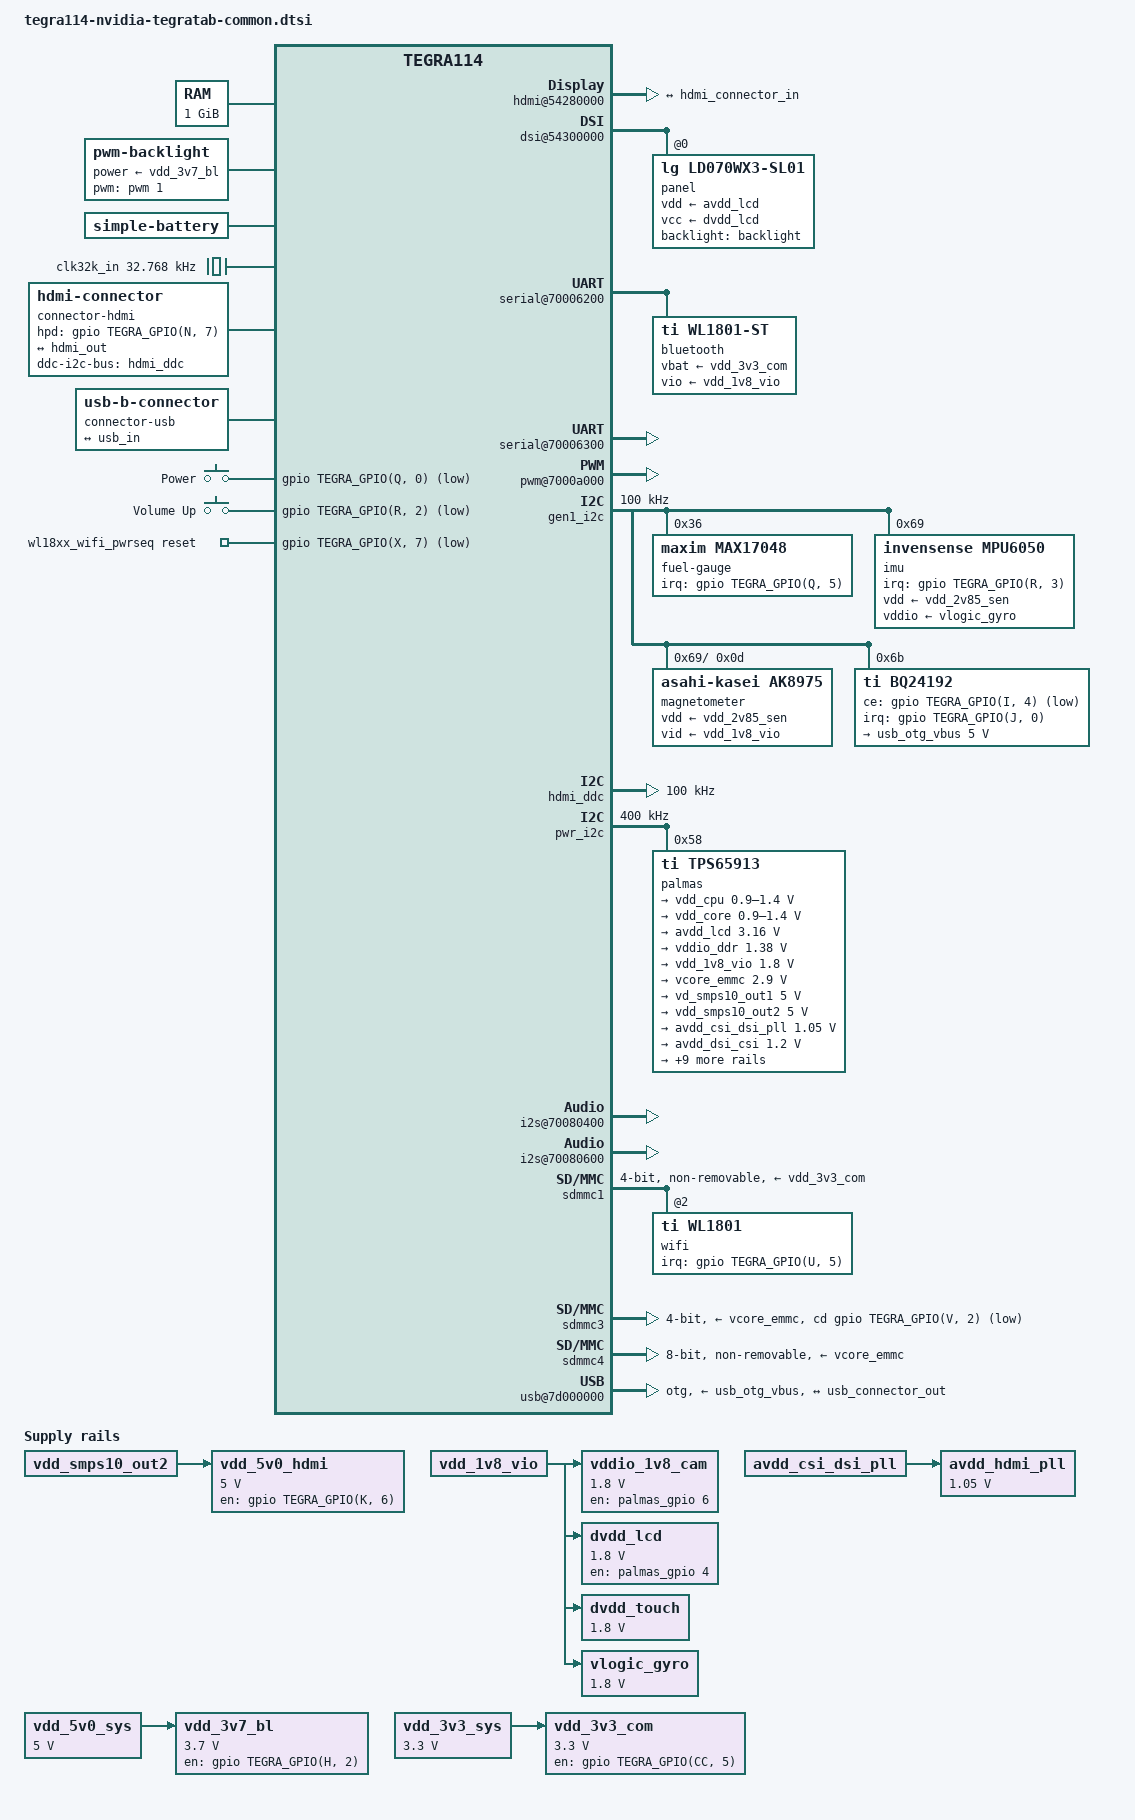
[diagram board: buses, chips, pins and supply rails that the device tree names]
// SPDX-License-Identifier: GPL-2.0

#include <dt-bindings/input/gpio-keys.h>
#include <dt-bindings/input/input.h>
#include <dt-bindings/thermal/thermal.h>

#include "tegra114.dtsi"

/ {
	compatible = "nvidia,tn7", "nvidia,tegra114";
	chassis-type = "tablet";

	aliases {
		mmc0 = &sdmmc4; /* eMMC */
		mmc1 = &sdmmc3; /* uSD slot */
		mmc2 = &sdmmc1; /* WiFi */

		rtc0 = &palmas;
		rtc1 = "/rtc@7000e000";

		serial0 = &uartd; /* Console */
		serial1 = &uartc; /* Bluetooth */
	};

	chosen {
		stdout-path = "serial0:115200n8";
	};

	firmware {
		trusted-foundations {
			compatible = "tlm,trusted-foundations";
			tlm,version-major = <2>;
			tlm,version-minor = <8>;
		};
	};

	memory@80000000 {
		reg = <0x80000000 0x40000000>;
	};

	reserved-memory {
		#address-cells = <1>;
		#size-cells = <1>;
		ranges;

		linux,cma@80000000 {
			compatible = "shared-dma-pool";
			alloc-ranges = <0x80000000 0x30000000>;
			size = <0x10000000>;		/* 256MiB */
			linux,cma-default;
			reusable;
		};

		bootloader-firmware@b7e00000 {
			reg = <0xb7e00000 0x8000000>;   /* 128MB */
			no-map;
		};

		trustzone@bfe00000 {
			reg = <0xbfe00000 0x200000>;	/* 2MB */
			no-map;
		};
	};

	host1x@50000000 {
		hdmi@54280000 {
			status = "okay";

			hdmi-supply = <&vdd_5v0_hdmi>;
			pll-supply = <&avdd_hdmi_pll>;
			vdd-supply = <&avdd_hdmi>;

			port@0 {
				hdmi_out: endpoint {
					remote-endpoint = <&hdmi_connector_in>;
				};
			};
		};

		dsi@54300000 {
			status = "okay";

			avdd-dsi-csi-supply = <&avdd_dsi_csi>;

			panel@0 {
				compatible = "lg,ld070wx3-sl01";
				reg = <0>;

				vdd-supply = <&avdd_lcd>;
				vcc-supply = <&dvdd_lcd>;

				backlight = <&backlight>;
			};
		};
	};

	clock@60006000 {
		emc-timings-1 {
			nvidia,ram-code = <1>;

			timing-12750000 {
				clock-frequency = <12750000>;
				nvidia,parent-clock-frequency = <408000000>;
				clocks = <&tegra_car TEGRA114_CLK_PLL_P>;
				clock-names = "emc-parent";
			};

			timing-20400000 {
				clock-frequency = <20400000>;
				nvidia,parent-clock-frequency = <408000000>;
				clocks = <&tegra_car TEGRA114_CLK_PLL_P>;
				clock-names = "emc-parent";
			};

			timing-40800000 {
				clock-frequency = <40800000>;
				nvidia,parent-clock-frequency = <408000000>;
				clocks = <&tegra_car TEGRA114_CLK_PLL_P>;
				clock-names = "emc-parent";
			};

			timing-68000000 {
				clock-frequency = <68000000>;
				nvidia,parent-clock-frequency = <408000000>;
				clocks = <&tegra_car TEGRA114_CLK_PLL_P>;
				clock-names = "emc-parent";
			};

			timing-102000000 {
				clock-frequency = <102000000>;
				nvidia,parent-clock-frequency = <408000000>;
				clocks = <&tegra_car TEGRA114_CLK_PLL_P>;
				clock-names = "emc-parent";
			};

			timing-204000000 {
				clock-frequency = <204000000>;
				nvidia,parent-clock-frequency = <408000000>;
				clocks = <&tegra_car TEGRA114_CLK_PLL_P>;
				clock-names = "emc-parent";
			};

			timing-312000000 {
				clock-frequency = <312000000>;
				nvidia,parent-clock-frequency = <624000000>;
				clocks = <&tegra_car TEGRA114_CLK_PLL_C>;
				clock-names = "emc-parent";
			};

			timing-408000000 {
				clock-frequency = <408000000>;
				nvidia,parent-clock-frequency = <408000000>;
				clocks = <&tegra_car TEGRA114_CLK_PLL_P>;
				clock-names = "emc-parent";
			};

			timing-624000000 {
				clock-frequency = <624000000>;
				nvidia,parent-clock-frequency = <624000000>;
				clocks = <&tegra_car TEGRA114_CLK_PLL_C>;
				clock-names = "emc-parent";
			};

			timing-792000000 {
				clock-frequency = <792000000>;
				nvidia,parent-clock-frequency = <792000000>;
				clocks = <&tegra_car TEGRA114_CLK_PLL_M>;
				clock-names = "emc-parent";
			};
		};
	};

//	gpio@6000d000 {
//		otg-iusb-hog {
//			gpio-hog;
//			gpios = <TEGRA_GPIO(I, 4) GPIO_ACTIVE_HIGH>;
//			output-high;
//		};
//		rt5639-codec-hog {
//			gpio-hog;
//			gpios = <TEGRA_GPIO(P, 3) GPIO_ACTIVE_HIGH>,
//				<TEGRA_GPIO(P, 1) GPIO_ACTIVE_HIGH>,
//				<TEGRA_GPIO(V, 0) GPIO_ACTIVE_HIGH>;
//			output-high;
//		};
//	};

	vde@6001a000 {
		assigned-clocks = <&tegra_car TEGRA114_CLK_VDE>;
		assigned-clock-parents = <&tegra_car TEGRA114_CLK_PLL_P>;
		assigned-clock-rates = <408000000>;
	};

	pinmux@70000868 {
		pinctrl-names = "default";
		pinctrl-0 = <&state_default>;

		state_default: pinmux {
			/* ULPI pinmux */
			ulpi-data0 {
				nvidia,pins = "ulpi_data0_po1",
					      "ulpi_data1_po2",
					      "ulpi_data2_po3",
					      "ulpi_data5_po6",
					      "ulpi_data6_po7",
					      "ulpi_data7_po0";
				nvidia,function = "ulpi";
				nvidia,pull = <TEGRA_PIN_PULL_NONE>;
				nvidia,tristate = <TEGRA_PIN_DISABLE>;
				nvidia,enable-input = <TEGRA_PIN_ENABLE>;
			};
			ulpi-data3 {
				nvidia,pins = "ulpi_data3_po4",
					      "ulpi_data4_po5";
				nvidia,function = "ulpi";
				nvidia,pull = <TEGRA_PIN_PULL_UP>;
				nvidia,tristate = <TEGRA_PIN_DISABLE>;
				nvidia,enable-input = <TEGRA_PIN_ENABLE>;
			};

			/* SPI1 pinmux */
			ulpi-clk {
				nvidia,pins = "ulpi_clk_py0",
					      "ulpi_nxt_py2",
					      "ulpi_stp_py3";
				nvidia,function = "spi1";
				nvidia,pull = <TEGRA_PIN_PULL_NONE>;
				nvidia,tristate = <TEGRA_PIN_DISABLE>;
				nvidia,enable-input = <TEGRA_PIN_DISABLE>;
			};
			ulpi-dir {
				nvidia,pins = "ulpi_dir_py1";
				nvidia,function = "spi1";
				nvidia,pull = <TEGRA_PIN_PULL_NONE>;
				nvidia,tristate = <TEGRA_PIN_DISABLE>;
				nvidia,enable-input = <TEGRA_PIN_ENABLE>;
			};

			/* I2S pinmux */
			dap1-pins {
				nvidia,pins = "dap1_fs_pn0",
					      "dap1_din_pn1",
					      "dap1_dout_pn2",
					      "dap1_sclk_pn3";
				nvidia,function = "rsvd4";
				nvidia,pull = <TEGRA_PIN_PULL_DOWN>;
				nvidia,tristate = <TEGRA_PIN_ENABLE>;
				nvidia,enable-input = <TEGRA_PIN_DISABLE>;
			};
			dap2-dout {
				nvidia,pins = "dap2_fs_pa2",
					      "dap2_sclk_pa3",
					      "dap2_dout_pa5";
				nvidia,function = "i2s1";
				nvidia,pull = <TEGRA_PIN_PULL_NONE>;
				nvidia,tristate = <TEGRA_PIN_DISABLE>;
				nvidia,enable-input = <TEGRA_PIN_DISABLE>;
			};
			dap2-din {
				nvidia,pins = "dap2_din_pa4";
				nvidia,function = "i2s1";
				nvidia,pull = <TEGRA_PIN_PULL_NONE>;
				nvidia,tristate = <TEGRA_PIN_DISABLE>;
				nvidia,enable-input = <TEGRA_PIN_ENABLE>;
			};
			dap3-fs-pp0 {
				nvidia,pins = "dap3_fs_pp0",
					      "dap3_din_pp1",
					      "dap3_dout_pp2",
					      "dap3_sclk_pp3";
				nvidia,function = "i2s2";
				nvidia,pull = <TEGRA_PIN_PULL_DOWN>;
				nvidia,tristate = <TEGRA_PIN_ENABLE>;
				nvidia,enable-input = <TEGRA_PIN_DISABLE>;
			};
			pv0 {
				nvidia,pins = "pv0";
				nvidia,function = "rsvd2";
				nvidia,pull = <TEGRA_PIN_PULL_DOWN>;
				nvidia,tristate = <TEGRA_PIN_ENABLE>;
				nvidia,enable-input = <TEGRA_PIN_DISABLE>;
			};
			pv1 {
				nvidia,pins = "pv1";
				nvidia,function = "rsvd1";
				nvidia,pull = <TEGRA_PIN_PULL_DOWN>;
				nvidia,tristate = <TEGRA_PIN_ENABLE>;
				nvidia,enable-input = <TEGRA_PIN_DISABLE>;
			};
			dap4-din {
				nvidia,pins = "dap4_din_pp5";
				nvidia,function = "i2s3";
				nvidia,pull = <TEGRA_PIN_PULL_NONE>;
				nvidia,tristate = <TEGRA_PIN_DISABLE>;
				nvidia,enable-input = <TEGRA_PIN_ENABLE>;
			};
			dap4-dout {
				nvidia,pins = "dap4_fs_pp4",
					      "dap4_dout_pp6",
					      "dap4_sclk_pp7";
				nvidia,function = "i2s3";
				nvidia,pull = <TEGRA_PIN_PULL_NONE>;
				nvidia,tristate = <TEGRA_PIN_DISABLE>;
				nvidia,enable-input = <TEGRA_PIN_DISABLE>;
			};

			/* SDMMC1 pinmux */
			sdmmc1-clk {
				nvidia,pins = "sdmmc1_clk_pz0";
				nvidia,function = "sdmmc1";
				nvidia,pull = <TEGRA_PIN_PULL_NONE>;
				nvidia,tristate = <TEGRA_PIN_DISABLE>;
				nvidia,enable-input = <TEGRA_PIN_ENABLE>;
			};
			sdmmc1-cmd {
				nvidia,pins = "sdmmc1_cmd_pz1",
					      "sdmmc1_dat0_py7",
					      "sdmmc1_dat1_py6",
					      "sdmmc1_dat2_py5",
					      "sdmmc1_dat3_py4";
				nvidia,function = "sdmmc1";
				nvidia,pull = <TEGRA_PIN_PULL_UP>;
				nvidia,tristate = <TEGRA_PIN_DISABLE>;
				nvidia,enable-input = <TEGRA_PIN_ENABLE>;
			};
			sdmmc1-wp-n {
				nvidia,pins = "sdmmc1_wp_n_pv3";
				nvidia,function = "sdmmc1";
				nvidia,pull = <TEGRA_PIN_PULL_NONE>;
				nvidia,tristate = <TEGRA_PIN_DISABLE>;
				nvidia,enable-input = <TEGRA_PIN_DISABLE>;
			};

			/* SDMMC3 pinmux */
			sdmmc3-clk {
				nvidia,pins = "sdmmc3_clk_pa6";
				nvidia,function = "sdmmc3";
				nvidia,pull = <TEGRA_PIN_PULL_NONE>;
				nvidia,tristate = <TEGRA_PIN_DISABLE>;
				nvidia,enable-input = <TEGRA_PIN_DISABLE>;
			};
			sdmmc3-cmd {
				nvidia,pins = "sdmmc3_cmd_pa7",
					      "sdmmc3_dat0_pb7",
					      "sdmmc3_dat1_pb6",
					      "sdmmc3_dat2_pb5",
					      "sdmmc3_dat3_pb4",
					      "sdmmc3_cd_n_pv2";
				nvidia,function = "sdmmc3";
				nvidia,pull = <TEGRA_PIN_PULL_UP>;
				nvidia,tristate = <TEGRA_PIN_DISABLE>;
				nvidia,enable-input = <TEGRA_PIN_ENABLE>;
			};
			sdmmc3-clk-lb {
				nvidia,pins = "sdmmc3_clk_lb_out_pee4",
					      "sdmmc3_clk_lb_in_pee5";
				nvidia,function = "sdmmc3";
				nvidia,pull = <TEGRA_PIN_PULL_UP>;
				nvidia,tristate = <TEGRA_PIN_DISABLE>;
				nvidia,enable-input = <TEGRA_PIN_ENABLE>;
			};

			/* SDMMC4 pinmux */
			sdmmc4-clk {
				nvidia,pins = "sdmmc4_clk_pcc4";
				nvidia,function = "sdmmc4";
				nvidia,pull = <TEGRA_PIN_PULL_NONE>;
				nvidia,tristate = <TEGRA_PIN_DISABLE>;
				nvidia,enable-input = <TEGRA_PIN_ENABLE>;
			};
			sdmmc4-cmd {
				nvidia,pins = "sdmmc4_cmd_pt7",
					      "sdmmc4_dat0_paa0",
					      "sdmmc4_dat1_paa1",
					      "sdmmc4_dat2_paa2",
					      "sdmmc4_dat3_paa3",
					      "sdmmc4_dat4_paa4",
					      "sdmmc4_dat5_paa5",
					      "sdmmc4_dat6_paa6",
					      "sdmmc4_dat7_paa7";
				nvidia,function = "sdmmc4";
				nvidia,pull = <TEGRA_PIN_PULL_UP>;
				nvidia,tristate = <TEGRA_PIN_DISABLE>;
				nvidia,enable-input = <TEGRA_PIN_ENABLE>;
			};

			/* EXTPERIPH pinmux */
			clk1-req {
				nvidia,pins = "clk1_req_pee2";
				nvidia,function = "rsvd3";
				nvidia,pull = <TEGRA_PIN_PULL_DOWN>;
				nvidia,tristate = <TEGRA_PIN_ENABLE>;
				nvidia,enable-input = <TEGRA_PIN_DISABLE>;
			};
			clk1-out {
				nvidia,pins = "clk1_out_pw4";
				nvidia,function = "extperiph1";
				nvidia,pull = <TEGRA_PIN_PULL_NONE>;
				nvidia,tristate = <TEGRA_PIN_DISABLE>;
				nvidia,enable-input = <TEGRA_PIN_DISABLE>;
			};
			clk2-req {
				nvidia,pins = "clk2_req_pcc5";
				nvidia,function = "rsvd2";
				nvidia,pull = <TEGRA_PIN_PULL_NONE>;
				nvidia,tristate = <TEGRA_PIN_DISABLE>;
				nvidia,enable-input = <TEGRA_PIN_DISABLE>;
			};
			clk2-out {
				nvidia,pins = "clk2_out_pw5";
				nvidia,function = "extperiph2";
				nvidia,pull = <TEGRA_PIN_PULL_NONE>;
				nvidia,tristate = <TEGRA_PIN_DISABLE>;
				nvidia,enable-input = <TEGRA_PIN_DISABLE>;
			};
			clk3-req-pee1 {
				nvidia,pins = "clk3_req_pee1";
				nvidia,function = "rsvd2";
				nvidia,pull = <TEGRA_PIN_PULL_NONE>;
				nvidia,tristate = <TEGRA_PIN_DISABLE>;
				nvidia,enable-input = <TEGRA_PIN_DISABLE>;
			};
			clk3-out {
				nvidia,pins = "clk3_out_pee0";
				nvidia,function = "extperiph3";
				nvidia,pull = <TEGRA_PIN_PULL_NONE>;
				nvidia,tristate = <TEGRA_PIN_DISABLE>;
				nvidia,enable-input = <TEGRA_PIN_DISABLE>;
			};

			dvfs-pinmux {
				nvidia,pins = "dvfs_pwm_px0",
					      "dvfs_clk_px2";
				nvidia,function = "cldvfs";
				nvidia,pull = <TEGRA_PIN_PULL_NONE>;
				nvidia,tristate = <TEGRA_PIN_DISABLE>;
				nvidia,enable-input = <TEGRA_PIN_DISABLE>;
			};

			/* HDMI pinmux */
			hdmi-irq {
				nvidia,pins = "hdmi_int_pn7";
				nvidia,function = "rsvd1";
				nvidia,pull = <TEGRA_PIN_PULL_DOWN>;
				nvidia,tristate = <TEGRA_PIN_DISABLE>;
				nvidia,enable-input = <TEGRA_PIN_ENABLE>;
				nvidia,rcv-sel = <TEGRA_PIN_DISABLE>;
			};
			hdmi-cec {
				nvidia,pins = "hdmi_cec_pee3";
				nvidia,function = "cec";
				nvidia,pull = <TEGRA_PIN_PULL_NONE>;
				nvidia,tristate = <TEGRA_PIN_DISABLE>;
				nvidia,enable-input = <TEGRA_PIN_ENABLE>;
				nvidia,open-drain = <TEGRA_PIN_DISABLE>;
			};

			/* I2C pinmux */
			gen1-i2c {
				nvidia,pins = "gen1_i2c_scl_pc4",
					      "gen1_i2c_sda_pc5";
				nvidia,function = "i2c1";
				nvidia,pull = <TEGRA_PIN_PULL_NONE>;
				nvidia,tristate = <TEGRA_PIN_DISABLE>;
				nvidia,enable-input = <TEGRA_PIN_ENABLE>;
				nvidia,open-drain = <TEGRA_PIN_ENABLE>;
			};
			gen2-i2c {
				nvidia,pins = "gen2_i2c_scl_pt5",
					      "gen2_i2c_sda_pt6";
				nvidia,function = "i2c2";
				nvidia,pull = <TEGRA_PIN_PULL_NONE>;
				nvidia,tristate = <TEGRA_PIN_DISABLE>;
				nvidia,enable-input = <TEGRA_PIN_ENABLE>;
				nvidia,open-drain = <TEGRA_PIN_ENABLE>;
			};
			cam-i2c {
				nvidia,pins = "cam_i2c_scl_pbb1",
					      "cam_i2c_sda_pbb2";
				nvidia,function = "i2c3";
				nvidia,pull = <TEGRA_PIN_PULL_NONE>;
				nvidia,tristate = <TEGRA_PIN_DISABLE>;
				nvidia,enable-input = <TEGRA_PIN_ENABLE>;
				nvidia,open-drain = <TEGRA_PIN_ENABLE>;
			};
			ddc-scl-pv4 {
				nvidia,pins = "ddc_scl_pv4",
					      "ddc_sda_pv5";
				nvidia,function = "i2c4";
				nvidia,pull = <TEGRA_PIN_PULL_NONE>;
				nvidia,tristate = <TEGRA_PIN_DISABLE>;
				nvidia,enable-input = <TEGRA_PIN_ENABLE>;
				nvidia,rcv-sel = <TEGRA_PIN_DISABLE>;
			};
			pwr-i2c {
				nvidia,pins = "pwr_i2c_scl_pz6",
					      "pwr_i2c_sda_pz7";
				nvidia,function = "i2cpwr";
				nvidia,pull = <TEGRA_PIN_PULL_NONE>;
				nvidia,tristate = <TEGRA_PIN_DISABLE>;
				nvidia,enable-input = <TEGRA_PIN_ENABLE>;
				nvidia,open-drain = <TEGRA_PIN_ENABLE>;
			};

			/* UARTA pinmux */
			uarta-out {
				nvidia,pins = "kb_row9_ps1";
				nvidia,function = "uarta";
				nvidia,pull = <TEGRA_PIN_PULL_NONE>;
				nvidia,tristate = <TEGRA_PIN_DISABLE>;
				nvidia,enable-input = <TEGRA_PIN_DISABLE>;
			};
			uarta-in {
				nvidia,pins = "kb_row10_ps2";
				nvidia,function = "uarta";
				nvidia,pull = <TEGRA_PIN_PULL_NONE>;
				nvidia,tristate = <TEGRA_PIN_DISABLE>;
				nvidia,enable-input = <TEGRA_PIN_ENABLE>;
			};

			/* UARTB pinmux */
			uart2-cts-rts {
				nvidia,pins = "uart2_cts_n_pj5",
					      "uart2_rts_n_pj6";
				nvidia,function = "rsvd3";
				nvidia,pull = <TEGRA_PIN_PULL_DOWN>;
				nvidia,tristate = <TEGRA_PIN_ENABLE>;
				nvidia,enable-input = <TEGRA_PIN_DISABLE>;
			};

			/* UARTC pinmux */
			uart3-cts-rxd {
				nvidia,pins = "uart3_cts_n_pa1",
					      "uart3_rxd_pw7";
				nvidia,function = "uartc";
				nvidia,pull = <TEGRA_PIN_PULL_UP>;
				nvidia,tristate = <TEGRA_PIN_DISABLE>;
				nvidia,enable-input = <TEGRA_PIN_ENABLE>;
			};
			uart3-rts-txd {
				nvidia,pins = "uart3_rts_n_pc0",
					      "uart3_txd_pw6";
				nvidia,function = "uartc";
				nvidia,pull = <TEGRA_PIN_PULL_NONE>;
				nvidia,tristate = <TEGRA_PIN_DISABLE>;
				nvidia,enable-input = <TEGRA_PIN_DISABLE>;
			};

			/* UARTD pinmux */
			gmi-a17 {
				nvidia,pins = "gmi_a17_pb0";
				nvidia,function = "uartd";
				nvidia,pull = <TEGRA_PIN_PULL_UP>;
				nvidia,tristate = <TEGRA_PIN_DISABLE>;
				nvidia,enable-input = <TEGRA_PIN_ENABLE>;
			};
			gmi-a18 {
				nvidia,pins = "gmi_a18_pb1";
				nvidia,function = "uartd";
				nvidia,pull = <TEGRA_PIN_PULL_NONE>;
				nvidia,tristate = <TEGRA_PIN_DISABLE>;
				nvidia,enable-input = <TEGRA_PIN_ENABLE>;
			};
			uartd-out {
				nvidia,pins = "gmi_a16_pj7",
					      "gmi_a19_pk7";
				nvidia,function = "uartd";
				nvidia,pull = <TEGRA_PIN_PULL_NONE>;
				nvidia,tristate = <TEGRA_PIN_DISABLE>;
				nvidia,enable-input = <TEGRA_PIN_DISABLE>;
			};

			/* PORT U */
			pu0 {
				nvidia,pins = "pu0";
				nvidia,function = "rsvd3";
				nvidia,pull = <TEGRA_PIN_PULL_DOWN>;
				nvidia,tristate = <TEGRA_PIN_ENABLE>;
				nvidia,enable-input = <TEGRA_PIN_DISABLE>;
			};
			pu1-2 {
				nvidia,pins = "pu1", "pu2";
				nvidia,function = "rsvd1";
				nvidia,pull = <TEGRA_PIN_PULL_DOWN>;
				nvidia,tristate = <TEGRA_PIN_ENABLE>;
				nvidia,enable-input = <TEGRA_PIN_DISABLE>;
			};
			pu3 {
				nvidia,pins = "pu3";
				nvidia,function = "pwm0";
				nvidia,pull = <TEGRA_PIN_PULL_DOWN>;
				nvidia,tristate = <TEGRA_PIN_ENABLE>;
				nvidia,enable-input = <TEGRA_PIN_DISABLE>;
			};
			pu4 {
				nvidia,pins = "pu4";
				nvidia,function = "pwm1";
				nvidia,pull = <TEGRA_PIN_PULL_DOWN>;
				nvidia,tristate = <TEGRA_PIN_ENABLE>;
				nvidia,enable-input = <TEGRA_PIN_DISABLE>;
			};
			pu5 {
				nvidia,pins = "pu5";
				nvidia,function = "pwm2";
				nvidia,pull = <TEGRA_PIN_PULL_UP>;
				nvidia,tristate = <TEGRA_PIN_DISABLE>;
				nvidia,enable-input = <TEGRA_PIN_ENABLE>;
			};
			pu6 {
				nvidia,pins = "pu6";
				nvidia,function = "pwm3";
				nvidia,pull = <TEGRA_PIN_PULL_NONE>;
				nvidia,tristate = <TEGRA_PIN_DISABLE>;
				nvidia,enable-input = <TEGRA_PIN_ENABLE>;
			};

			/* GMI section */
			gmi-wp-n-pc7 {
				nvidia,pins = "gmi_wp_n_pc7",
					      "gmi_adv_n_pk0",
					      "gmi_cs0_n_pj0",
					      "gmi_wr_n_pi0";
				nvidia,function = "rsvd1";
				nvidia,pull = <TEGRA_PIN_PULL_UP>;
				nvidia,tristate = <TEGRA_PIN_DISABLE>;
				nvidia,enable-input = <TEGRA_PIN_ENABLE>;
			};
			gmi-iordy-pi5 {
				nvidia,pins = "gmi_iordy_pi5";
				nvidia,function = "rsvd2";
				nvidia,pull = <TEGRA_PIN_PULL_DOWN>;
				nvidia,tristate = <TEGRA_PIN_ENABLE>;
				nvidia,enable-input = <TEGRA_PIN_DISABLE>;
			};
			gmi-wait-pi7 {
				nvidia,pins = "gmi_wait_pi7";
				nvidia,function = "nand";
				nvidia,pull = <TEGRA_PIN_PULL_NONE>;
				nvidia,tristate = <TEGRA_PIN_DISABLE>;
				nvidia,enable-input = <TEGRA_PIN_DISABLE>;
			};
			gmi-clk-pk1 {
				nvidia,pins = "gmi_clk_pk1",
					      "gmi_ad10_ph2",
					      "gmi_ad11_ph3",
					      "gmi_ad14_ph6",
					      "gmi_cs3_n_pk4";
				nvidia,function = "gmi";
				nvidia,pull = <TEGRA_PIN_PULL_NONE>;
				nvidia,tristate = <TEGRA_PIN_DISABLE>;
				nvidia,enable-input = <TEGRA_PIN_DISABLE>;
			};
			gmi-cs2-n-pk3 {
				nvidia,pins = "gmi_cs2_n_pk3";
				nvidia,function = "gmi";
				nvidia,pull = <TEGRA_PIN_PULL_UP>;
				nvidia,tristate = <TEGRA_PIN_DISABLE>;
				nvidia,enable-input = <TEGRA_PIN_ENABLE>;
			};
			gmi-cs4-n-pk2 {
				nvidia,pins = "gmi_cs4_n_pk2";
				nvidia,function = "gmi";
				nvidia,pull = <TEGRA_PIN_PULL_NONE>;
				nvidia,tristate = <TEGRA_PIN_ENABLE>;
				nvidia,enable-input = <TEGRA_PIN_ENABLE>;
			};
			gmi-cs6-n-pi3 {
				nvidia,pins = "gmi_cs6_n_pi3";
				nvidia,function = "nand";
				nvidia,pull = <TEGRA_PIN_PULL_DOWN>;
				nvidia,tristate = <TEGRA_PIN_ENABLE>;
				nvidia,enable-input = <TEGRA_PIN_DISABLE>;
			};
			gmi-cs7-n-pi6 {
				nvidia,pins = "gmi_cs7_n_pi6";
				nvidia,function = "nand";
				nvidia,pull = <TEGRA_PIN_PULL_NONE>;
				nvidia,tristate = <TEGRA_PIN_DISABLE>;
				nvidia,enable-input = <TEGRA_PIN_ENABLE>;
			};
			gmi-ad0-pg0 {
				nvidia,pins = "gmi_ad0_pg0";
				nvidia,function = "rsvd1";
				nvidia,pull = <TEGRA_PIN_PULL_NONE>;
				nvidia,tristate = <TEGRA_PIN_DISABLE>;
				nvidia,enable-input = <TEGRA_PIN_DISABLE>;
			};
			gmi-ad1-pg1 {
				nvidia,pins = "gmi_ad1_pg1",
					      "gmi_ad4_pg4",
					      "gmi_ad5_pg5",
					      "gmi_ad6_pg6",
					      "gmi_ad7_pg7";
				nvidia,function = "rsvd1";
				nvidia,pull = <TEGRA_PIN_PULL_DOWN>;
				nvidia,tristate = <TEGRA_PIN_ENABLE>;
				nvidia,enable-input = <TEGRA_PIN_DISABLE>;
			};
			gmi-ad2-pg2 {
				nvidia,pins = "gmi_ad2_pg2",
					      "gmi_ad3_pg3",
					      "gmi_oe_n_pi1";
				nvidia,function = "rsvd1";
				nvidia,pull = <TEGRA_PIN_PULL_NONE>;
				nvidia,tristate = <TEGRA_PIN_DISABLE>;
				nvidia,enable-input = <TEGRA_PIN_ENABLE>;
			};
			gmi-ad8-ph0 {
				nvidia,pins = "gmi_ad8_ph0";
				nvidia,function = "gmi";
				nvidia,pull = <TEGRA_PIN_PULL_DOWN>;
				nvidia,tristate = <TEGRA_PIN_ENABLE>;
				nvidia,enable-input = <TEGRA_PIN_DISABLE>;
			};
			gmi-ad9 {
				nvidia,pins = "gmi_ad9_ph1";
				nvidia,function = "pwm1";
				nvidia,pull = <TEGRA_PIN_PULL_NONE>;
				nvidia,tristate = <TEGRA_PIN_DISABLE>;
				nvidia,enable-input = <TEGRA_PIN_DISABLE>;
			};
			gmi-ad12-ph4 {
				nvidia,pins = "gmi_ad12_ph4";
				nvidia,function = "rsvd4";
				nvidia,pull = <TEGRA_PIN_PULL_UP>;
				nvidia,tristate = <TEGRA_PIN_DISABLE>;
				nvidia,enable-input = <TEGRA_PIN_ENABLE>;
			};
			gmi-ad13-ph5 {
				nvidia,pins = "gmi_ad13_ph5";
				nvidia,function = "rsvd4";
				nvidia,pull = <TEGRA_PIN_PULL_NONE>;
				nvidia,tristate = <TEGRA_PIN_DISABLE>;
				nvidia,enable-input = <TEGRA_PIN_DISABLE>;
			};
			gmi-ad15-ph7 {
				nvidia,pins = "gmi_ad15_ph7";
				nvidia,function = "gmi";
				nvidia,pull = <TEGRA_PIN_PULL_DOWN>;
				nvidia,tristate = <TEGRA_PIN_ENABLE>;
				nvidia,enable-input = <TEGRA_PIN_DISABLE>;
			};
			gmi-dqs-p-pj3 {
				nvidia,pins = "gmi_dqs_p_pj3";
				nvidia,function = "nand";
				nvidia,pull = <TEGRA_PIN_PULL_UP>;
				nvidia,tristate = <TEGRA_PIN_DISABLE>;
				nvidia,enable-input = <TEGRA_PIN_ENABLE>;
			};
			gmi-rst-n-pi4 {
				nvidia,pins = "gmi_rst_n_pi4";
				nvidia,function = "rsvd4";
				nvidia,pull = <TEGRA_PIN_PULL_NONE>;
				nvidia,tristate = <TEGRA_PIN_DISABLE>;
				nvidia,enable-input = <TEGRA_PIN_DISABLE>;
			};
			gmi-clk-lb {
				nvidia,pins = "gmi_clk_lb";
				nvidia,function = "gmi";
				nvidia,pull = <TEGRA_PIN_PULL_NONE>;
				nvidia,tristate = <TEGRA_PIN_DISABLE>;
				nvidia,enable-input = <TEGRA_PIN_ENABLE>;
			};

			/* VI_ALT3 pinmux */
			cam-mclk {
				nvidia,pins = "pbb0", "cam_mclk_pcc0";
				nvidia,function = "vi_alt3";
				nvidia,pull = <TEGRA_PIN_PULL_NONE>;
				nvidia,tristate = <TEGRA_PIN_DISABLE>;
				nvidia,enable-input = <TEGRA_PIN_DISABLE>;
			};

			port-bb {
				nvidia,pins = "pbb3", "pbb4", "pbb5",
					      "pbb6",	"pbb7";
				nvidia,function = "rsvd4";
				nvidia,pull = <TEGRA_PIN_PULL_NONE>;
				nvidia,tristate = <TEGRA_PIN_DISABLE>;
				nvidia,enable-input = <TEGRA_PIN_DISABLE>;
			};

			port-cc {
				nvidia,pins = "pcc1", "pcc2";
				nvidia,function = "rsvd2";
				nvidia,pull = <TEGRA_PIN_PULL_DOWN>;
				nvidia,tristate = <TEGRA_PIN_DISABLE>;
				nvidia,enable-input = <TEGRA_PIN_ENABLE>;
			};

			jtag-rtck {
				nvidia,pins = "jtag_rtck";
				nvidia,function = "rtck";
				nvidia,pull = <TEGRA_PIN_PULL_NONE>;
				nvidia,tristate = <TEGRA_PIN_DISABLE>;
				nvidia,enable-input = <TEGRA_PIN_ENABLE>;
			};

			/* KBC pinmux */
			kb-row0-pr0 {
				nvidia,pins = "kb_row0_pr0",
					      "kb_row1_pr1";
				nvidia,function = "rsvd2";
				nvidia,pull = <TEGRA_PIN_PULL_NONE>;
				nvidia,tristate = <TEGRA_PIN_DISABLE>;
				nvidia,enable-input = <TEGRA_PIN_DISABLE>;
			};
			kb-row2-pr2 {
				nvidia,pins = "kb_row2_pr2",
					      "kb_col0_pq0";
				nvidia,function = "kbc";
				nvidia,pull = <TEGRA_PIN_PULL_UP>;
				nvidia,tristate = <TEGRA_PIN_DISABLE>;
				nvidia,enable-input = <TEGRA_PIN_ENABLE>;
			};
			kb-row3-pr3 {
				nvidia,pins = "kb_row3_pr3";
				nvidia,function = "rsvd3";
				nvidia,pull = <TEGRA_PIN_PULL_UP>;
				nvidia,tristate = <TEGRA_PIN_DISABLE>;
				nvidia,enable-input = <TEGRA_PIN_ENABLE>;
			};
			kb-row4-pr4 {
				nvidia,pins = "kb_row4_pr4",
					      "kb_row5_pr5",
					      "kb_row6_pr6",
					      "kb_col3_pq3",
					      "kb_col4_pq4";
				nvidia,function = "kbc";
				nvidia,pull = <TEGRA_PIN_PULL_DOWN>;
				nvidia,tristate = <TEGRA_PIN_ENABLE>;
				nvidia,enable-input = <TEGRA_PIN_DISABLE>;
			};
			kb-row7-pr7 {
				nvidia,pins = "kb_row7_pr7",
					      "kb_col2_pq2",
					      "kb_col5_pq5";
				nvidia,function = "rsvd2";
				nvidia,pull = <TEGRA_PIN_PULL_UP>;
				nvidia,tristate = <TEGRA_PIN_DISABLE>;
				nvidia,enable-input = <TEGRA_PIN_ENABLE>;
			};
			kb-row8-ps0 {
				nvidia,pins = "kb_row8_ps0",
					      "kb_col1_pq1",
					      "kb_col6_pq6",
					      "kb_col7_pq7";
				nvidia,function = "rsvd2";
				nvidia,pull = <TEGRA_PIN_PULL_DOWN>;
				nvidia,tristate = <TEGRA_PIN_ENABLE>;
				nvidia,enable-input = <TEGRA_PIN_DISABLE>;
			};

			/* CORE pinmux */
			sys-clk-req {
				nvidia,pins = "sys_clk_req_pz5";
				nvidia,function = "rsvd2";
				nvidia,pull = <TEGRA_PIN_PULL_DOWN>;
				nvidia,tristate = <TEGRA_PIN_ENABLE>;
				nvidia,enable-input = <TEGRA_PIN_DISABLE>;
			};
			clk-32k-out {
				nvidia,pins = "clk_32k_out_pa0",
					      "gmi_cs1_n_pj2";
				nvidia,function = "soc";
				nvidia,pull = <TEGRA_PIN_PULL_UP>;
				nvidia,tristate = <TEGRA_PIN_ENABLE>;
				nvidia,enable-input = <TEGRA_PIN_ENABLE>;
			};
			clk-32k-in {
				nvidia,pins = "clk_32k_in";
				nvidia,function = "clk";
				nvidia,pull = <TEGRA_PIN_PULL_NONE>;
				nvidia,tristate = <TEGRA_PIN_DISABLE>;
				nvidia,enable-input = <TEGRA_PIN_ENABLE>;
			};
			core-pwr-req {
				nvidia,pins = "core_pwr_req";
				nvidia,function = "pwron";
				nvidia,pull = <TEGRA_PIN_PULL_NONE>;
				nvidia,tristate = <TEGRA_PIN_DISABLE>;
				nvidia,enable-input = <TEGRA_PIN_DISABLE>;
			};
			cpu-pwr-req {
				nvidia,pins = "cpu_pwr_req";
				nvidia,function = "cpu";
				nvidia,pull = <TEGRA_PIN_PULL_NONE>;
				nvidia,tristate = <TEGRA_PIN_DISABLE>;
				nvidia,enable-input = <TEGRA_PIN_DISABLE>;
			};
			pwr-int-n {
				nvidia,pins = "pwr_int_n";
				nvidia,function = "pmi";
				nvidia,pull = <TEGRA_PIN_PULL_UP>;
				nvidia,tristate = <TEGRA_PIN_DISABLE>;
				nvidia,enable-input = <TEGRA_PIN_ENABLE>;
			};
			owr {
				nvidia,pins = "owr";
				nvidia,function = "rsvd2";
				nvidia,pull = <TEGRA_PIN_PULL_DOWN>;
				nvidia,tristate = <TEGRA_PIN_ENABLE>;
				nvidia,enable-input = <TEGRA_PIN_DISABLE>;
				nvidia,rcv-sel = <TEGRA_PIN_DISABLE>;
			};
			reset-out-n {
				nvidia,pins = "reset_out_n";
				nvidia,function = "reset_out_n";
				nvidia,pull = <TEGRA_PIN_PULL_NONE>;
				nvidia,tristate = <TEGRA_PIN_DISABLE>;
				nvidia,enable-input = <TEGRA_PIN_DISABLE>;
			};

			/* AUD pinmux */
			gpio-x1-aud-px1 {
				nvidia,pins = "gpio_x1_aud_px1";
				nvidia,function = "rsvd2";
				nvidia,pull = <TEGRA_PIN_PULL_UP>;
				nvidia,tristate = <TEGRA_PIN_DISABLE>;
				nvidia,enable-input = <TEGRA_PIN_ENABLE>;
			};
			gpio-x3-aud-px3 {
				nvidia,pins = "gpio_x3_aud_px3";
				nvidia,function = "rsvd3";
				nvidia,pull = <TEGRA_PIN_PULL_DOWN>;
				nvidia,tristate = <TEGRA_PIN_ENABLE>;
				nvidia,enable-input = <TEGRA_PIN_DISABLE>;
			};
			gpio-x4-aud-px4 {
				nvidia,pins = "gpio_x4_aud_px4",
					      "gpio_x5_aud_px5",
					      "gpio_x7_aud_px7";
				nvidia,function = "rsvd1";
				nvidia,pull = <TEGRA_PIN_PULL_DOWN>;
				nvidia,tristate = <TEGRA_PIN_ENABLE>;
				nvidia,enable-input = <TEGRA_PIN_DISABLE>;
			};
			gpio-x6-aud-px6 {
				nvidia,pins = "gpio_x6_aud_px6";
				nvidia,function = "rsvd4";
				nvidia,pull = <TEGRA_PIN_PULL_DOWN>;
				nvidia,tristate = <TEGRA_PIN_ENABLE>;
				nvidia,enable-input = <TEGRA_PIN_DISABLE>;
			};
			gpio-w2-aud-pw2 {
				nvidia,pins = "gpio_w2_aud_pw2";
				nvidia,function = "rsvd2";
				nvidia,pull = <TEGRA_PIN_PULL_DOWN>;
				nvidia,tristate = <TEGRA_PIN_ENABLE>;
				nvidia,enable-input = <TEGRA_PIN_DISABLE>;
			};
			gpio-w3-aud-pw3 {
				nvidia,pins = "gpio_w3_aud_pw3";
				nvidia,function = "spi6";
				nvidia,pull = <TEGRA_PIN_PULL_UP>;
				nvidia,tristate = <TEGRA_PIN_DISABLE>;
				nvidia,enable-input = <TEGRA_PIN_ENABLE>;
			};

			usb-vbus-en {
				nvidia,pins = "usb_vbus_en0_pn4",
					      "usb_vbus_en1_pn5";
				nvidia,function = "rsvd2";
				nvidia,pull = <TEGRA_PIN_PULL_DOWN>;
				nvidia,tristate = <TEGRA_PIN_ENABLE>;
				nvidia,enable-input = <TEGRA_PIN_DISABLE>;
				nvidia,open-drain = <TEGRA_PIN_DISABLE>;
			};

			/* GPIO power/drive control */
			drive-sdio1 {
				nvidia,pins = "drive_sdio1";
				nvidia,high-speed-mode = <TEGRA_PIN_ENABLE>;
				nvidia,schmitt = <TEGRA_PIN_DISABLE>;
				nvidia,pull-down-strength = <36>;
				nvidia,pull-up-strength = <20>;
				nvidia,slew-rate-rising = <TEGRA_PIN_SLEW_RATE_SLOW>;
				nvidia,slew-rate-falling = <TEGRA_PIN_SLEW_RATE_SLOW>;
			};
			drive-sdio3 {
				nvidia,pins = "drive_sdio3";
				nvidia,high-speed-mode = <TEGRA_PIN_ENABLE>;
				nvidia,schmitt = <TEGRA_PIN_DISABLE>;
				nvidia,pull-down-strength = <22>;
				nvidia,pull-up-strength = <36>;
				nvidia,slew-rate-rising = <TEGRA_PIN_SLEW_RATE_FASTEST>;
				nvidia,slew-rate-falling = <TEGRA_PIN_SLEW_RATE_FASTEST>;
			};
			drive-gma {
				nvidia,pins = "drive_gma";
				nvidia,high-speed-mode = <TEGRA_PIN_ENABLE>;
				nvidia,schmitt = <TEGRA_PIN_DISABLE>;
				nvidia,pull-down-strength = <2>;
				nvidia,pull-up-strength = <2>;
				nvidia,slew-rate-rising = <TEGRA_PIN_SLEW_RATE_FASTEST>;
				nvidia,slew-rate-falling = <TEGRA_PIN_SLEW_RATE_FASTEST>;
			};
		};
	};

	serial@70006200 {
		compatible = "nvidia,tegra114-hsuart", "nvidia,tegra30-hsuart";
		reset-names = "serial";
		/delete-property/ reg-shift;
		status = "okay";

		nvidia,adjust-baud-rates = <0 9600 100>,
					   <9600 115200 200>,
					   <1000000 4000000 136>;

		bluetooth {
			compatible = "ti,wl1801-st";
			max-speed = <3000000>;

			vbat-supply = <&vdd_3v3_com>;
			vio-supply = <&vdd_1v8_vio>;
		};
	};

	serial@70006300 {
		/delete-property/ dmas;
		/delete-property/ dma-names;
		status = "okay";
	};

	pwm@7000a000 {
		status = "okay";
	};

	gen1_i2c: i2c@7000c000 {
		status = "okay";
		clock-frequency = <100000>;

#if 0
		/* Capella CM3217 ambient light sensor */
		light-sensor@10 {
			compatible = "capella,cm3218";
			reg = <0x10>;

			vdd-supply = <&vdd_2v85_sen>;
		};

		/* 0x11 ??? */
#endif

#if 0
static struct tpa6130a2_platform_data tpa6130a2_pdata = {
	/*.power_gpio = TEGRA_GPIO_HP_EN,*/
};

static struct i2c_board_info __initdata tpa6130a2_board_info = {
	I2C_BOARD_INFO("tpa6130a2", 0x60),
	.platform_data = &tpa6130a2_pdata,
};
#endif

		fuel-gauge@36 {
			compatible = "maxim,max17048";
			reg = <0x36>;

			interrupt-parent = <&gpio>;
			interrupts = <TEGRA_GPIO(Q, 5) IRQ_TYPE_EDGE_FALLING>;

			monitored-battery = <&battery>;
			power-supplies = <&bq24192>;

			maxim,alert-low-soc-level = <10>;
			maxim,double-soc;

			wakeup-source;
		};

		imu@69 {
			compatible = "invensense,mpu6050";
			reg = <0x69>;

			interrupt-parent = <&gpio>;
			interrupts = <TEGRA_GPIO(R, 3) IRQ_TYPE_LEVEL_HIGH>;

			vdd-supply = <&vdd_2v85_sen>;
			vddio-supply = <&vlogic_gyro>;

			i2c-gate {
				#address-cells = <1>;
				#size-cells = <0>;

				magnetometer@d {
					compatible = "asahi-kasei,ak8975";
					reg = <0x0d>;

					/* no DRDY (polling) */

					vdd-supply = <&vdd_2v85_sen>;
					vid-supply = <&vdd_1v8_vio>;
				};
			};
		};

		/* TI BQ24193 */
		bq24192: charger@6b {
			compatible = "ti,bq24192";
			reg = <0x6b>;

			interrupt-parent = <&gpio>;
			interrupts = <TEGRA_GPIO(J, 0) IRQ_TYPE_EDGE_FALLING>;

			ce-gpios = <&gpio TEGRA_GPIO(I, 4) GPIO_ACTIVE_LOW>;

			monitored-battery = <&battery>;

			omit-battery-class;
			ti,system-minimum-microvolt = <3100000>;

			usb_otg_vbus: usb-otg-vbus {
				regulator-name = "usb_otg_vbus";
				regulator-min-microvolt = <5000000>;
				regulator-max-microvolt = <5000000>;
			};
		};
	};

#if 0
	i2c@7000c500 {
		status = "okay";
		clock-frequency = <400000>;

		ad5823: coil@c {
			compatible = "adi,ad5823";
			reg = <0x0c>;

			VANA-supply = <&avdd_2v8_front>;
			enable-gpios = <&gpio TEGRA_GPIO(BB, 7) GPIO_ACTIVE_HIGH>;
		};

		rear-camera@10 {
			compatible = "ovti,ov5693";
			reg = <0x10>;

			reset-gpios = <&gpio TEGRA_GPIO(BB, 5) GPIO_ACTIVE_LOW>;

			clocks = <&tegra_car TEGRA114_CLK_CSUS>;
			clock-names = "xvclk";

			avdd-supply = <&avdd_2v7_rear>;
			dvdd-supply = <&vdd_1v2_cam>; // ??
			dovdd-supply = <&vddio_1v8_cam>;

			orientation = <1>; /* Rear camera */
			rotation = <90>;

			lens-focus = <&ad5823>;

			assigned-clocks = <&tegra_car TEGRA114_CLK_VI_SENSOR>,
					  <&tegra_car TEGRA114_CLK_CSUS>;
			assigned-clock-rates = <24000000>;
			assigned-clock-parents = <&tegra_car TEGRA114_CLK_PLL_P>,
						 <&tegra_car TEGRA114_CLK_VI_SENSOR>;

			port {
				rear_camera_output: endpoint {
					data-lanes = <1 2>;
					bus-type = <MEDIA_BUS_TYPE_CSI2_DPHY>;
					link-frequencies = /bits/ 64 <419200000>;
					remote-endpoint = <&csia_input>;
				};
			};
		};

		/* 0x21 ov7695 this seems to be correct one */

		/* Aptina 1/6" HD SOC (MT9M114) */
		front-camera@48 {
			compatible = "onnn,mt9m114";
			reg = <0x48>;

			reset-gpios = <&gpio TEGRA_GPIO(BB, 3) GPIO_ACTIVE_LOW>;

			clocks = <&tegra_car TEGRA114_CLK_CSUS>;

			vddio-supply = <&vddio_1v8_cam>;
			vdd-supply = <&vdd_1v8_cam>; // ??
			vaa-supply = <&avdd_2v8_front>;

			orientation = <0>; /* Front camera */

			assigned-clocks = <&tegra_car TEGRA114_CLK_VI_SENSOR>,
					  <&tegra_car TEGRA114_CLK_CSUS>;
			assigned-clock-rates = <24000000>;
			assigned-clock-parents = <&tegra_car TEGRA114_CLK_PLL_P>,
						 <&tegra_car TEGRA114_CLK_VI_SENSOR>;

			port {
				front_camera_output: endpoint {
					data-lanes = <3>;
					bus-type = <MEDIA_BUS_TYPE_CSI2_DPHY>;
					link-frequencies = /bits/ 64 <384000000>;
					remote-endpoint = <&csib_input>;
				};
			};
		};
	};
#endif

	hdmi_ddc: i2c@7000c700 {
		status = "okay";
		clock-frequency = <100000>;
	};

	pwr_i2c: i2c@7000d000 {
		status = "okay";
		clock-frequency = <400000>;

		palmas: pmic@58 {
			compatible = "ti,tps65913", "ti,palmas";
			reg = <0x58>;
			interrupts = <GIC_SPI 86 IRQ_TYPE_LEVEL_HIGH>;

			#interrupt-cells = <2>;
			interrupt-controller;

			ti,system-power-controller;

			palmas_extcon: extcon {
				compatible = "ti,palmas-usb-vid";

				ti,enable-vbus-detection;
				ti,enable-id-detection;

				ti,wakeup;
			};

			palmas_gpio: gpio {
				compatible = "ti,palmas-gpio";
				gpio-controller;
				#gpio-cells = <2>;
			};

			pinmux {
				compatible = "ti,tps65913-pinctrl";
				ti,palmas-enable-dvfs1;

				pinctrl-names = "default";
				pinctrl-0 = <&palmas_default>;

				palmas_default: pinmux {
					pin_gpio0 {
						pins = "gpio0";
						function = "gpio";
					};

					pin_gpio1 {
						pins = "gpio1";
						function = "gpio";
					};

					pin_gpio2 {
						pins = "gpio2";
						function = "gpio";
					};

					pin_gpio3 {
						pins = "gpio3";
						function = "gpio";
					};

					pin_gpio4 {
						pins = "gpio4";
						function = "gpio";
					};

					pin_gpio5 {
						pins = "gpio5";
						function = "gpio";
					};

					pin_gpio6 {
						pins = "gpio6";
						function = "gpio";
					};

					pin_gpio7 {
						pins = "gpio7";
						function = "gpio";
					};

					pin_powergood {
						pins = "powergood";
						function = "powergood";
					};

					pin_vac {
						pins = "vac";
						function = "vac";
					};
				};
			};

			pmic {
				compatible = "ti,tps65913-pmic", "ti,palmas-pmic";

				ldo1-in-supply = <&vddio_ddr>;
				ldo2-in-supply = <&vddio_ddr>;
				ldo5-in-supply = <&vcore_emmc>;
				ldo6-in-supply = <&vcore_emmc>;
				ldo7-in-supply = <&vcore_emmc>;
				ldo9-in-supply = <&vcore_emmc>;
				ldoln-in-supply = <&vdd_smps10_out2>;

				regulators {
					vdd_cpu: smps123 {
						regulator-name = "vdd_cpu";
						regulator-min-microvolt = <900000>;
						regulator-max-microvolt = <1400000>;
						regulator-always-on;
						regulator-boot-on;
						ti,roof-floor = <1>;
						ti,mode-sleep = <3>;
					};

					vdd_core: smps45 {
						regulator-name = "vdd_core";
						regulator-min-microvolt = <900000>;
						regulator-max-microvolt = <1400000>;
						regulator-always-on;
						regulator-boot-on;
						ti,roof-floor = <3>;
					};

					avdd_lcd: smps6 {
						regulator-name = "vdd_lcd_hv";
						regulator-min-microvolt = <3160000>;
						regulator-max-microvolt = <3160000>;
						regulator-boot-on;
					};

					vddio_ddr: smps7 {
						regulator-name = "vddio_ddr";
						regulator-min-microvolt = <1380000>;
						regulator-max-microvolt = <1380000>;
						regulator-always-on;
						regulator-boot-on;
					};

					vdd_1v8_vio: smps8 {
						regulator-name = "vdd_1v8";
						regulator-min-microvolt = <1800000>;
						regulator-max-microvolt = <1800000>;
						regulator-always-on;
						regulator-boot-on;
					};

					vcore_emmc: smps9 {
						regulator-name = "vdd_emmc";
						regulator-min-microvolt = <2900000>;
						regulator-max-microvolt = <2900000>;
						regulator-boot-on;
					};

					smps10_out1 {
						regulator-name = "vd_smps10_out1";
						regulator-min-microvolt = <5000000>;
						regulator-max-microvolt = <5000000>;
						regulator-always-on;
						regulator-boot-on;
					};

					vdd_smps10_out2: smps10_out2 {
						regulator-name = "vd_smps10_out2";
						regulator-min-microvolt = <5000000>;
						regulator-max-microvolt = <5000000>;
						regulator-always-on;
						regulator-boot-on;
					};

					avdd_csi_dsi_pll: ldo1 {
						regulator-name = "avdd_csi_dsi_pll";
						regulator-min-microvolt = <1050000>;
						regulator-max-microvolt = <1050000>;
						regulator-always-on;
						regulator-boot-on;
						ti,roof-floor = <3>;
					};

					avdd_dsi_csi: ldo2 {
						regulator-name = "avdd_dsi_csi";
						regulator-min-microvolt = <1200000>;
						regulator-max-microvolt = <1200000>;
						regulator-boot-on;
					};

					ldo3 {
						regulator-name = "vpp_fuse";
						regulator-min-microvolt = <1800000>;
						regulator-max-microvolt = <1800000>;
					};

					avdd_touch: ldo4 {
						regulator-name = "avdd_ts";
						regulator-min-microvolt = <2850000>;
						regulator-max-microvolt = <2850000>;
					};

					avdd_2v8_front: ldo5 {
						regulator-name = "avdd_front_cam";
						regulator-min-microvolt = <2800000>;
						regulator-max-microvolt = <2800000>;
					};

					vdd_2v85_sen: ldo6 {
						regulator-name = "vdd_dev";
						regulator-min-microvolt = <2850000>;
						regulator-max-microvolt = <2850000>;
					};

					avdd_2v7_rear: ldo7 {
						regulator-name = "avdd_rear_cam";
						regulator-min-microvolt = <2700000>;
						regulator-max-microvolt = <2700000>;
					};

					ldo8 {
						regulator-name = "vdd_rtc";
						regulator-min-microvolt = <950000>;
						regulator-max-microvolt = <950000>;
						regulator-always-on;
						regulator-boot-on;
						ti,enable-ldo8-tracking;
					};

					vddio_usd: ldo9 {
						regulator-name = "vddio_usd";
						regulator-min-microvolt = <1800000>;
						regulator-max-microvolt = <2900000>;
					};

					avdd_hdmi: ldoln {
						regulator-name = "avdd_hdmi";
						regulator-min-microvolt = <3300000>;
						regulator-max-microvolt = <3300000>;
						regulator-boot-on;
					};

					avdd_usb: ldousb {
						regulator-name = "avdd_usb";
						regulator-min-microvolt = <3300000>;
						regulator-max-microvolt = <3300000>;
						regulator-always-on;
						regulator-boot-on;
						ti,roof-floor = <3>;
					};
				};
			};

			rtc {
				compatible = "ti,palmas-rtc";
				interrupt-parent = <&palmas>;
				interrupts = <8 IRQ_TYPE_NONE>;
			};
		};
	};

#if 0
	spi@7000d400 {
		status = "okay";
		spi-max-frequency = <25000000>;

		touchscreen@0 {
			compatible = "maxim,maxim-sti";
			reg = <0x0>;

			spi-max-frequency = <12000000>;

			nvidia,rx-clk-tap-delay = <0>;
			nvidia,tx-clk-tap-delay = <0>;

			interrupt-parent = <&gpio>;
			interrupts = <TEGRA_GPIO(K, 2) IRQ_TYPE_EDGE_RISING>;

			irq-gpio = <&gpio TEGRA_GPIO(K, 2) GPIO_ACTIVE_HIGH>;
			reset-gpio = <&gpio TEGRA_GPIO(K, 4) GPIO_ACTIVE_LOW>;

			avdd-supply = <&avdd_touch>;
			dvdd-supply = <&dvdd_touch>;
		};
	};
#endif

	pmc@7000e400 {
//		nvidia,invert-interrupt; // maybe not needed, check
		nvidia,suspend-mode = <1>;
		nvidia,cpu-pwr-good-time = <300>;
		nvidia,cpu-pwr-off-time = <300>;
		nvidia,core-pwr-good-time = <641 3845>;
		nvidia,core-pwr-off-time = <2000>;
		nvidia,core-power-req-active-high;
		nvidia,sys-clock-req-active-high;
		core-supply = <&vdd_core>;

		/* Clear DEV_ON bit in DEV_CTRL register of TPS65913 PMIC */
		i2c-thermtrip {
			nvidia,i2c-controller-id = <4>;
			nvidia,bus-addr = <0x58>;
			nvidia,reg-addr = <0xa0>;
			nvidia,reg-data = <0x00>;
		};
	};

	memory-controller@70019000 {
		emc-timings-1 {
			/* P1640 Micron MT41K128M16-125 DDR3 792MHz */
			nvidia,ram-code = <1>;

			timing-12750000 {
				clock-frequency = <12750000>;

				nvidia,emem-configuration = < 0x40040001 0x8000003f
					0x00000001 0x00000001 0x00000002 0x00000000
					0x00000001 0x00000001 0x00000002 0x00000008
					0x00000002 0x00000001 0x00000003 0x00000006
					0x06030102 0x000a0402 0x77e30303 0x001f0000 >;
			};

			timing-20400000 {
				clock-frequency = <20400000>;

				nvidia,emem-configuration = < 0x40020001 0x80000046
					0x00000001 0x00000001 0x00000002 0x00000000
					0x00000001 0x00000001 0x00000002 0x00000008
					0x00000002 0x00000001 0x00000003 0x00000006
					0x06030102 0x000a0402 0x75430303 0x001f0000 >;
			};

			timing-40800000 {
				clock-frequency = <40800000>;

				nvidia,emem-configuration = < 0xa0000001 0x8000005b
					0x00000001 0x00000001 0x00000002 0x00000000
					0x00000001 0x00000001 0x00000002 0x00000008
					0x00000002 0x00000001 0x00000003 0x00000006
					0x06030102 0x000a0402 0x73630303 0x001f0000 >;
			};

			timing-68000000 {
				clock-frequency = <68000000>;

				nvidia,emem-configuration = < 0x00000001 0x80000076
					0x00000001 0x00000001 0x00000002 0x00000000
					0x00000001 0x00000001 0x00000002 0x00000008
					0x00000002 0x00000001 0x00000003 0x00000006
					0x06030102 0x000a0402 0x72c30403 0x001f0000 >;
			};

			timing-102000000 {
				clock-frequency = <102000000>;

				nvidia,emem-configuration = < 0x08000001 0x80000098
					0x00000001 0x00000001 0x00000003 0x00000000
					0x00000002 0x00000001 0x00000002 0x00000008
					0x00000002 0x00000001 0x00000003 0x00000006
					0x06030102 0x000a0403 0x72830504 0x001f0000 >;
			};

			timing-204000000 {
				clock-frequency = <204000000>;

				nvidia,emem-configuration = < 0x01000003 0x800000fe
					0x00000001 0x00000001 0x00000005 0x00000002
					0x00000004 0x00000001 0x00000002 0x00000008
					0x00000002 0x00000001 0x00000003 0x00000006
					0x06030102 0x000a0405 0x72440a06 0x001f0000 >;
			};

			timing-312000000 {
				clock-frequency = <312000000>;

				nvidia,emem-configuration = < 0x0b000004 0x8000016a
					0x00000001 0x00000002 0x00000007 0x00000004
					0x00000006 0x00000001 0x00000002 0x00000007
					0x00000002 0x00000002 0x00000004 0x00000006
					0x06040202 0x000b0607 0x76e50f08 0x001f0000 >;
			};

			timing-408000000 {
				clock-frequency = <408000000>;

				nvidia,emem-configuration = < 0x02000006 0x80000190
					0x00000001 0x00000002 0x0000000a 0x00000006
					0x00000008 0x00000001 0x00000002 0x00000009
					0x00000002 0x00000002 0x00000004 0x00000006
					0x06040202 0x000e070a 0x7547130b 0x001f0000 >;
			};

			timing-624000000 {
				clock-frequency = <624000000>;

				nvidia,emem-configuration = < 0x06000009 0x80000190
					0x00000003 0x00000004 0x0000000f 0x00000009
					0x0000000c 0x00000001 0x00000003 0x0000000b
					0x00000002 0x00000002 0x00000005 0x00000007
					0x07050202 0x00130b0f 0x736a1d10 0x001f0000 >;
			};

			timing-792000000 {
				clock-frequency = <792000000>;

				nvidia,emem-configuration = < 0x0e00000b 0x80000190
					0x00000004 0x00000005 0x00000013 0x0000000c
					0x0000000f 0x00000002 0x00000003 0x0000000c
					0x00000002 0x00000002 0x00000006 0x00000008
					0x08060202 0x00170e13 0x72cc2414 0x001f0000 >;
			};
		};
	};

	external-memory-controller@7001b000 {
		emc-timings-1 {
			/* P1640 Micron MT41K128M16-125 DDR3 792MHz */
			nvidia,ram-code = <1>;

			timing-12750000 {
				clock-frequency = <12750000>;

				nvidia,emc-zcal-cnt-long = <0x00000042>;
				nvidia,emc-auto-cal-interval = <0x001fffff>;
				nvidia,emc-cfg = <0x7320000e>;
				nvidia,emc-mode-1 = <0x80100003>;
				nvidia,emc-mode-2 = <0x80200008>;
				nvidia,emc-mode-4 = <0x00000000>;
				nvidia,emc-mode-reset = <0x80001221>;
				nvidia,emc-auto-cal-config = <0xa0f10000>;
				nvidia,emc-auto-cal-config2 = <0x00000000>;
				nvidia,emc-auto-cal-config3 = <0x00000000>;
				nvidia,emc-ctt-term-ctrl = <0x00000802>;
				nvidia,emc-mrs-wait-cnt = <0x000c000c>;
				nvidia,emc-sel-dpd-ctrl = <0x00040320>;
				nvidia,emc-xm2dqspadctrl2 = <0x0000a11c>;
				nvidia,emc-zcal-interval = <0x00000000>;

				nvidia,emc-configuration =  < 0x00000000
					0x00000003 0x00000000 0x00000000 0x00000004
					0x0000000a 0x00000003 0x0000000b 0x00000000
					0x00000000 0x00000003 0x00000001 0x00000000
					0x00000005 0x00000005 0x00000006 0x00000006
					0x00000004 0x00000004 0x00010000 0x00000000
					0x00000000 0x00000004 0x00000009 0x0000000d
					0x0000000d 0x00000060 0x00000000 0x00000018
					0x00000002 0x00000002 0x00000001 0x00000000
					0x00000007 0x0000000f 0x00000005 0x00000005
					0x00000004 0x00000004 0x00000004 0x00000001
					0x00000000 0x00000004 0x00000005 0x00000064
					0x00000005 0x00000006 0x00000020 0x00000000
					0x0000aa88 0x002c00a0 0x00008000 0x0006c000
					0x0006c000 0x0006c000 0x0006c000 0x0006c000
					0x0006c000 0x0006c000 0x0006c000 0x00000000
					0x00000000 0x00000000 0x00000000 0x00000000
					0x00000000 0x00000000 0x00000000 0x00000000
					0x00000000 0x00000000 0x00000000 0x00000000
					0x00000000 0x00000000 0x00000000 0x00048000
					0x00048000 0x00048000 0x00048000 0x001112a0
					0x00000000 0x00000000 0x77ffc085 0x81f1f108
					0x03035504 0x0000003f 0x20820800 0x00208208
					0x0000003f 0x00000000 0x02000000 0x00000042
					0x000c000c 0x00000000 0x00000000 0x800001c6 >;
			};

			timing-20400000 {
				clock-frequency = <20400000>;

				nvidia,emc-zcal-cnt-long = <0x00000042>;
				nvidia,emc-auto-cal-interval = <0x001fffff>;
				nvidia,emc-cfg = <0x7320000e>;
				nvidia,emc-mode-1 = <0x80100003>;
				nvidia,emc-mode-2 = <0x80200008>;
				nvidia,emc-mode-4 = <0x00000000>;
				nvidia,emc-mode-reset = <0x80001221>;
				nvidia,emc-auto-cal-config = <0xa0f10000>;
				nvidia,emc-auto-cal-config2 = <0x00000000>;
				nvidia,emc-auto-cal-config3 = <0x00000000>;
				nvidia,emc-ctt-term-ctrl = <0x00000802>;
				nvidia,emc-mrs-wait-cnt = <0x000c000c>;
				nvidia,emc-sel-dpd-ctrl = <0x00040320>;
				nvidia,emc-xm2dqspadctrl2 = <0x0000a11c>;
				nvidia,emc-zcal-interval = <0x00000000>;

				nvidia,emc-configuration =  < 0x00000000
					0x00000003 0x00000000 0x00000000 0x00000004
					0x0000000a 0x00000003 0x0000000b 0x00000000
					0x00000000 0x00000003 0x00000001 0x00000000
					0x00000005 0x00000005 0x00000006 0x00000006
					0x00000004 0x00000004 0x00010000 0x00000000
					0x00000000 0x00000004 0x00000009 0x0000000d
					0x0000000d 0x0000009a 0x00000000 0x00000026
					0x00000002 0x00000002 0x00000001 0x00000000
					0x00000007 0x0000000f 0x00000005 0x00000006
					0x00000004 0x00000004 0x00000004 0x00000001
					0x00000000 0x00000004 0x00000005 0x000000a0
					0x00000005 0x00000006 0x00000020 0x00000000
					0x0000aa88 0x002c00a0 0x00008000 0x0006c000
					0x0006c000 0x0006c000 0x0006c000 0x0006c000
					0x0006c000 0x0006c000 0x0006c000 0x00000000
					0x00000000 0x00000000 0x00000000 0x00000000
					0x00000000 0x00000000 0x00000000 0x00000000
					0x00000000 0x00000000 0x00000000 0x00000000
					0x00000000 0x00000000 0x00000000 0x00048000
					0x00048000 0x00048000 0x00048000 0x001112a0
					0x00000000 0x00000000 0x77ffc085 0x81f1f108
					0x03035504 0x0000003f 0x20820800 0x00208208
					0x0000003f 0x00000000 0x02000000 0x00000042
					0x000c000c 0x00000000 0x00000000 0x8000023a >;
			};

			timing-40800000 {
				clock-frequency = <40800000>;

				nvidia,emc-zcal-cnt-long = <0x00000042>;
				nvidia,emc-auto-cal-interval = <0x001fffff>;
				nvidia,emc-cfg = <0x7320000e>;
				nvidia,emc-mode-1 = <0x80100003>;
				nvidia,emc-mode-2 = <0x80200008>;
				nvidia,emc-mode-4 = <0x00000000>;
				nvidia,emc-mode-reset = <0x80001221>;
				nvidia,emc-auto-cal-config = <0xa0f10000>;
				nvidia,emc-auto-cal-config2 = <0x00000000>;
				nvidia,emc-auto-cal-config3 = <0x00000000>;
				nvidia,emc-ctt-term-ctrl = <0x00000802>;
				nvidia,emc-mrs-wait-cnt = <0x000c000c>;
				nvidia,emc-sel-dpd-ctrl = <0x00040320>;
				nvidia,emc-xm2dqspadctrl2 = <0x0000a11c>;
				nvidia,emc-zcal-interval = <0x00000000>;

				nvidia,emc-configuration =  < 0x00000001
					0x00000006 0x00000001 0x00000000 0x00000004
					0x0000000a 0x00000003 0x0000000b 0x00000000
					0x00000000 0x00000003 0x00000001 0x00000000
					0x00000005 0x00000005 0x00000006 0x00000006
					0x00000004 0x00000004 0x00010000 0x00000000
					0x00000000 0x00000004 0x00000009 0x0000000d
					0x0000000d 0x00000134 0x00000000 0x0000004d
					0x00000002 0x00000002 0x00000001 0x00000000
					0x00000007 0x0000000f 0x00000007 0x0000000c
					0x00000004 0x00000004 0x00000004 0x00000002
					0x00000000 0x00000004 0x00000005 0x0000013f
					0x00000005 0x00000006 0x00000020 0x00000000
					0x0000aa88 0x002c00a0 0x00008000 0x0006c000
					0x0006c000 0x0006c000 0x0006c000 0x0006c000
					0x0006c000 0x0006c000 0x0006c000 0x00000000
					0x00000000 0x00000000 0x00000000 0x00000000
					0x00000000 0x00000000 0x00000000 0x00000000
					0x00000000 0x00000000 0x00000000 0x00000000
					0x00000000 0x00000000 0x00000000 0x00048000
					0x00048000 0x00048000 0x00048000 0x001112a0
					0x00000000 0x00000000 0x77ffc085 0x81f1f108
					0x03035504 0x0000003f 0x20820800 0x00208208
					0x0000003f 0x00000000 0x02000000 0x00000042
					0x000c000c 0x00000000 0x00000000 0x80000370 >;
			};

			timing-68000000 {
				clock-frequency = <68000000>;

				nvidia,emc-zcal-cnt-long = <0x00000042>;
				nvidia,emc-auto-cal-interval = <0x001fffff>;
				nvidia,emc-cfg = <0x7320000e>;
				nvidia,emc-mode-1 = <0x80100003>;
				nvidia,emc-mode-2 = <0x80200008>;
				nvidia,emc-mode-4 = <0x00000000>;
				nvidia,emc-mode-reset = <0x80001221>;
				nvidia,emc-auto-cal-config = <0xa0f10000>;
				nvidia,emc-auto-cal-config2 = <0x00000000>;
				nvidia,emc-auto-cal-config3 = <0x00000000>;
				nvidia,emc-ctt-term-ctrl = <0x00000802>;
				nvidia,emc-mrs-wait-cnt = <0x000c000c>;
				nvidia,emc-sel-dpd-ctrl = <0x00040320>;
				nvidia,emc-xm2dqspadctrl2 = <0x0000a11c>;
				nvidia,emc-zcal-interval = <0x00000000>;

				nvidia,emc-configuration =  < 0x00000003
					0x0000000a 0x00000002 0x00000000 0x00000004
					0x0000000a 0x00000003 0x0000000b 0x00000000
					0x00000000 0x00000003 0x00000001 0x00000000
					0x00000005 0x00000005 0x00000006 0x00000006
					0x00000004 0x00000004 0x00010000 0x00000000
					0x00000000 0x00000004 0x00000009 0x0000000d
					0x0000000d 0x00000202 0x00000000 0x00000080
					0x00000002 0x00000002 0x00000001 0x00000000
					0x00000008 0x0000000f 0x0000000c 0x00000013
					0x00000004 0x00000004 0x00000004 0x00000003
					0x00000000 0x00000004 0x00000005 0x00000213
					0x00000005 0x00000006 0x00000020 0x00000000
					0x0000aa88 0x002c00a0 0x00008000 0x0006c000
					0x0006c000 0x0006c000 0x0006c000 0x0006c000
					0x0006c000 0x0006c000 0x0006c000 0x00000000
					0x00000000 0x00000000 0x00000000 0x00000000
					0x00000000 0x00000000 0x00000000 0x00000000
					0x00000000 0x00000000 0x00000000 0x00000000
					0x00000000 0x00000000 0x00000000 0x00048000
					0x00048000 0x00048000 0x00048000 0x001112a0
					0x00000000 0x00000000 0x77ffc085 0x81f1f108
					0x03035504 0x0000003f 0x20820800 0x00208208
					0x0000003f 0x00000000 0x02000000 0x00000042
					0x000c000c 0x00000000 0x00000000 0x8000050e >;
			};

			timing-102000000 {
				clock-frequency = <102000000>;

				nvidia,emc-zcal-cnt-long = <0x00000042>;
				nvidia,emc-auto-cal-interval = <0x001fffff>;
				nvidia,emc-cfg = <0x7320000e>;
				nvidia,emc-mode-1 = <0x80100003>;
				nvidia,emc-mode-2 = <0x80200008>;
				nvidia,emc-mode-4 = <0x00000000>;
				nvidia,emc-mode-reset = <0x80001221>;
				nvidia,emc-auto-cal-config = <0xa0f10000>;
				nvidia,emc-auto-cal-config2 = <0x00000000>;
				nvidia,emc-auto-cal-config3 = <0x00000000>;
				nvidia,emc-ctt-term-ctrl = <0x00000802>;
				nvidia,emc-mrs-wait-cnt = <0x000c000c>;
				nvidia,emc-sel-dpd-ctrl = <0x00040320>;
				nvidia,emc-xm2dqspadctrl2 = <0x0000a11c>;
				nvidia,emc-zcal-interval = <0x00000000>;

				nvidia,emc-configuration =  < 0x00000004
					0x00000010 0x00000003 0x00000001 0x00000004
					0x0000000a 0x00000003 0x0000000b 0x00000001
					0x00000001 0x00000003 0x00000001 0x00000000
					0x00000005 0x00000005 0x00000006 0x00000006
					0x00000004 0x00000004 0x00010000 0x00000000
					0x00000000 0x00000004 0x00000009 0x0000000d
					0x0000000d 0x00000303 0x00000000 0x000000c0
					0x00000002 0x00000002 0x00000001 0x00000000
					0x0000000d 0x0000000f 0x00000012 0x0000001c
					0x00000004 0x00000004 0x00000004 0x00000005
					0x00000000 0x00000004 0x00000005 0x0000031c
					0x00000005 0x00000006 0x00000020 0x00000000
					0x0000aa88 0x002c00a0 0x00008000 0x0006c000
					0x0006c000 0x0006c000 0x0006c000 0x0006c000
					0x0006c000 0x0006c000 0x0006c000 0x00000000
					0x00000000 0x00000000 0x00000000 0x00000000
					0x00000000 0x00000000 0x00000000 0x00000000
					0x00000000 0x00000000 0x00000000 0x00000000
					0x00000000 0x00000000 0x00000000 0x00048000
					0x00048000 0x00048000 0x00048000 0x001112a0
					0x00000000 0x00000000 0x77ffc085 0x81f1f108
					0x03035504 0x0000003f 0x20820800 0x00208208
					0x0000003f 0x00000000 0x02000000 0x00000042
					0x000c000c 0x00000000 0x00000000 0x80000714 >;
			};

			timing-204000000 {
				clock-frequency = <204000000>;

				nvidia,emc-zcal-cnt-long = <0x00000042>;
				nvidia,emc-auto-cal-interval = <0x001fffff>;
				nvidia,emc-cfg = <0x7320000e>;
				nvidia,emc-mode-1 = <0x80100003>;
				nvidia,emc-mode-2 = <0x80200008>;
				nvidia,emc-mode-4 = <0x00000000>;
				nvidia,emc-mode-reset = <0x80001221>;
				nvidia,emc-auto-cal-config = <0xa0f10000>;
				nvidia,emc-auto-cal-config2 = <0x00000000>;
				nvidia,emc-auto-cal-config3 = <0x00000000>;
				nvidia,emc-ctt-term-ctrl = <0x00000802>;
				nvidia,emc-mrs-wait-cnt = <0x000c000c>;
				nvidia,emc-sel-dpd-ctrl = <0x00040320>;
				nvidia,emc-xm2dqspadctrl2 = <0x0000a11c>;
				nvidia,emc-zcal-interval = <0x00020000>;

				nvidia,emc-configuration =  < 0x00000009
					0x00000020 0x00000007 0x00000002 0x00000004
					0x0000000a 0x00000003 0x0000000b 0x00000002
					0x00000002 0x00000003 0x00000001 0x00000000
					0x00000005 0x00000005 0x00000007 0x00000006
					0x00000004 0x00000004 0x00010000 0x00000000
					0x00000000 0x00000004 0x00000009 0x0000000d
					0x0000000d 0x00000607 0x00000000 0x00000181
					0x00000002 0x00000002 0x00000001 0x00000000
					0x0000001d 0x0000000f 0x00000023 0x00000038
					0x00000004 0x00000004 0x00000004 0x00000009
					0x00000000 0x00000004 0x00000005 0x00000638
					0x00000006 0x00000004 0x00000020 0x00000000
					0x0000aa88 0x000000a0 0x00008000 0x0006c000
					0x0006c000 0x0006c000 0x0006c000 0x0006c000
					0x0006c000 0x0006c000 0x0006c000 0x00000000
					0x00000000 0x00000000 0x00000000 0x00000000
					0x00000000 0x00000000 0x00000000 0x00000000
					0x00000000 0x00000000 0x00000000 0x00000000
					0x00000000 0x00000000 0x00000000 0x00048000
					0x00048000 0x00048000 0x00048000 0x001112a0
					0x00000000 0x00000000 0x77ffc085 0x81f1f108
					0x05057404 0x0000003f 0x20820800 0x0079e79e
					0x0000003f 0x00000000 0x02000000 0x00000100
					0x000c000c 0x00000000 0x00000000 0x80000d22 >;
			};

			timing-312000000 {
				clock-frequency = <312000000>;

				nvidia,emc-zcal-cnt-long = <0x00000042>;
				nvidia,emc-auto-cal-interval = <0x001fffff>;
				nvidia,emc-cfg = <0x5300000e>;
				nvidia,emc-mode-1 = <0x80100002>;
				nvidia,emc-mode-2 = <0x80200000>;
				nvidia,emc-mode-4 = <0x00000000>;
				nvidia,emc-mode-reset = <0x80000321>;
				nvidia,emc-auto-cal-config = <0xa0f10000>;
				nvidia,emc-auto-cal-config2 = <0x00000000>;
				nvidia,emc-auto-cal-config3 = <0x00000000>;
				nvidia,emc-ctt-term-ctrl = <0x00000802>;
				nvidia,emc-mrs-wait-cnt = <0x0190000c>;
				nvidia,emc-sel-dpd-ctrl = <0x00040320>;
				nvidia,emc-xm2dqspadctrl2 = <0x0001013d>;
				nvidia,emc-zcal-interval = <0x00020000>;

				nvidia,emc-configuration =  < 0x0000000e
					0x00000030 0x00000009 0x00000003 0x00000004
					0x00000008 0x00000002 0x00000009 0x00000003
					0x00000003 0x00000002 0x00000001 0x00000000
					0x00000004 0x00000004 0x00000007 0x00000007
					0x00000005 0x00000004 0x00080006 0x00000000
					0x00000000 0x00000004 0x0000000b 0x0000000d
					0x0000000d 0x00000945 0x00000000 0x00000251
					0x00000001 0x00000008 0x00000001 0x00000000
					0x0000002e 0x0000000e 0x00000036 0x00000200
					0x00000004 0x00000004 0x00000004 0x0000000d
					0x00000000 0x00000004 0x00000005 0x00000986
					0x00000006 0x00000004 0x00000020 0x00000000
					0x0000ba88 0x002c00a0 0x00008000 0x00038000
					0x00038000 0x00038000 0x00038000 0x00038000
					0x00038000 0x00038000 0x00038000 0x00028000
					0x00028000 0x00028000 0x00028000 0x00028000
					0x00028000 0x00028000 0x00028000 0x00000000
					0x00000000 0x00000000 0x00000000 0x00000000
					0x00000000 0x00000000 0x00000000 0x00030000
					0x00030000 0x00030000 0x00030000 0x001112a0
					0x00000000 0x00000000 0x77ffc085 0x81f1f108
					0x03035504 0x00000000 0x10410400 0x00208208
					0x0000003f 0x00000000 0x02000000 0x00000100
					0x0190000c 0x00000000 0x00000000 0x80001395 >;
			};

			timing-408000000 {
				clock-frequency = <408000000>;

				nvidia,emc-zcal-cnt-long = <0x00000042>;
				nvidia,emc-auto-cal-interval = <0x001fffff>;
				nvidia,emc-cfg = <0x53000006>;
				nvidia,emc-mode-1 = <0x80100002>;
				nvidia,emc-mode-2 = <0x80200008>;
				nvidia,emc-mode-4 = <0x00000000>;
				nvidia,emc-mode-reset = <0x80000731>;
				nvidia,emc-auto-cal-config = <0xa0f10000>;
				nvidia,emc-auto-cal-config2 = <0x00000000>;
				nvidia,emc-auto-cal-config3 = <0x00000000>;
				nvidia,emc-ctt-term-ctrl = <0x00000802>;
				nvidia,emc-mrs-wait-cnt = <0x0181000c>;
				nvidia,emc-sel-dpd-ctrl = <0x00040320>;
				nvidia,emc-xm2dqspadctrl2 = <0x0001013d>;
				nvidia,emc-zcal-interval = <0x00020000>;

				nvidia,emc-configuration =  < 0x00000012
					0x00000040 0x0000000d 0x00000004 0x00000005
					0x00000009 0x00000002 0x0000000c 0x00000004
					0x00000004 0x00000002 0x00000001 0x00000000
					0x00000004 0x00000004 0x00000007 0x00000007
					0x00000005 0x00000004 0x00080006 0x00000000
					0x00000000 0x00000004 0x0000000c 0x0000000e
					0x0000000e 0x00000c2f 0x00000000 0x0000030b
					0x00000001 0x00000008 0x00000001 0x00000000
					0x0000003d 0x00000011 0x00000046 0x00000200
					0x00000004 0x00000004 0x00000004 0x00000011
					0x00000000 0x00000004 0x00000005 0x00000c70
					0x00000006 0x00000006 0x00000020 0x00000000
					0x0000ba88 0x002c0080 0x00008000 0x00028000
					0x00028000 0x00028000 0x00028000 0x00028000
					0x00028000 0x00028000 0x00028000 0x00000000
					0x00000000 0x00000000 0x00000000 0x00000000
					0x00000000 0x00000000 0x00000000 0x00000000
					0x00000000 0x00000000 0x00000000 0x00000000
					0x00000000 0x00000000 0x00000000 0x00020001
					0x00020001 0x00020001 0x00020001 0x001112a0
					0x00000000 0x00000000 0x77ffc085 0x81f1f108
					0x03035504 0x00000000 0x10410400 0x00208208
					0x0000003f 0x00000000 0x02000000 0x00000100
					0x0181000c 0x00000000 0x00000000 0x80001944 >;
			};

			timing-624000000 {
				clock-frequency = <624000000>;

				nvidia,emc-zcal-cnt-long = <0x00000042>;
				nvidia,emc-auto-cal-interval = <0x001fffff>;
				nvidia,emc-cfg = <0x53200000>;
				nvidia,emc-mode-1 = <0x80100002>;
				nvidia,emc-mode-2 = <0x80200010>;
				nvidia,emc-mode-4 = <0x00000000>;
				nvidia,emc-mode-reset = <0x80000b61>;
				nvidia,emc-auto-cal-config = <0xa0f10000>;
				nvidia,emc-auto-cal-config2 = <0x00000000>;
				nvidia,emc-auto-cal-config3 = <0x00000000>;
				nvidia,emc-ctt-term-ctrl = <0x00000802>;
				nvidia,emc-mrs-wait-cnt = <0x0160000c>;
				nvidia,emc-sel-dpd-ctrl = <0x00040320>;
				nvidia,emc-xm2dqspadctrl2 = <0x0000013d>;
				nvidia,emc-zcal-interval = <0x00020000>;

				nvidia,emc-configuration =  < 0x0000001d
					0x00000062 0x00000014 0x00000007 0x00000007
					0x0000000b 0x00000003 0x00000010 0x00000007
					0x00000007 0x00000003 0x00000001 0x00000000
					0x00000005 0x00000005 0x0000000a 0x0000000a
					0x00000008 0x00000004 0x000c000a 0x00000000
					0x00000000 0x00000007 0x0000000c 0x00000012
					0x00000012 0x000012c4 0x00000000 0x000004b1
					0x00000002 0x0000000d 0x00000001 0x00000000
					0x0000005e 0x00000015 0x0000006b 0x00000200
					0x00000005 0x00000005 0x00000005 0x00000019
					0x00000000 0x00000006 0x00000007 0x00001305
					0x00000009 0x00000006 0x00000020 0x00000000
					0x0000ba88 0xf00d0191 0x00008000 0x007fc00b
					0x007fc00b 0x007fc00b 0x007fc00b 0x007fc00b
					0x007fc00b 0x007fc00b 0x007fc00b 0x00000000
					0x00000000 0x00000000 0x00000000 0x00000000
					0x00000000 0x00000000 0x00000000 0x00000000
					0x00000000 0x00000000 0x00000000 0x00000000
					0x00000000 0x00000000 0x00000000 0x00000009
					0x00000009 0x00000009 0x00000009 0x001112a0
					0x00000000 0x00000000 0x77ffc085 0x81f1f108
					0x07077504 0x00000000 0x10410400 0x0028a28a
					0x0000003f 0x00000000 0x02000000 0x00000100
					0x0160000c 0x00000000 0x00000000 0x8000261a >;
			};

			timing-792000000 {
				clock-frequency = <792000000>;

				nvidia,emc-zcal-cnt-long = <0x00000042>;
				nvidia,emc-auto-cal-interval = <0x001fffff>;
				nvidia,emc-cfg = <0x53000000>;
				nvidia,emc-mode-1 = <0x80100002>;
				nvidia,emc-mode-2 = <0x80200218>;
				nvidia,emc-mode-4 = <0x00000000>;
				nvidia,emc-mode-reset = <0x80000d71>;
				nvidia,emc-auto-cal-config = <0xa0f10f0f>;
				nvidia,emc-auto-cal-config2 = <0x00000000>;
				nvidia,emc-auto-cal-config3 = <0x00000000>;
				nvidia,emc-ctt-term-ctrl = <0x00000802>;
				nvidia,emc-mrs-wait-cnt = <0x0147000c>;
				nvidia,emc-sel-dpd-ctrl = <0x00040000>;
				nvidia,emc-xm2dqspadctrl2 = <0x0000013d>;
				nvidia,emc-zcal-interval = <0x00020000>;

				nvidia,emc-configuration =  < 0x00000024
					0x0000007d 0x00000019 0x0000000a 0x00000009
					0x0000000d 0x00000004 0x00000013 0x0000000a
					0x0000000a 0x00000004 0x00000001 0x00000000
					0x00000006 0x00000006 0x0000000b 0x0000000b
					0x00000008 0x00000006 0x000d000a 0x00000000
					0x00000000 0x00000008 0x0000000d 0x00000014
					0x00000014 0x000017e4 0x00000000 0x000005f9
					0x00000003 0x00000012 0x00000001 0x00000000
					0x00000077 0x00000018 0x00000087 0x00000200
					0x00000005 0x00000005 0x00000005 0x00000020
					0x00000000 0x00000007 0x00000008 0x00001825
					0x0000000a 0x00000006 0x80000020 0x00000000
					0x0000ba88 0xf0070191 0x00008000 0x00004008
					0x00004008 0x00004008 0x00004008 0x00004008
					0x00004008 0x00004008 0x00004008 0x00000000
					0x00000000 0x00000000 0x00000000 0x00000000
					0x00000000 0x00000000 0x00000000 0x00000000
					0x00000000 0x00000000 0x00000000 0x00000000
					0x00000000 0x00000000 0x00000000 0x0000400a
					0x0000400a 0x0000400a 0x0000400a 0x001112a0
					0x00000000 0x00000000 0x77ffc084 0x81f1f508
					0x07076604 0x00000000 0x10410400 0x0028a28a
					0x0000003f 0x00000000 0x02000000 0x00000100
					0x0147000c 0x00000000 0x00000000 0x80003018 >;
			};
		};
	};

	ahub@70080000 {
		/* HIFI CODEC */
		i2s@70080400 {		/* i2s1 */
			status = "okay";
		};

		/* BT SCO */
		i2s@70080600 {		/* i2s3 */
			status = "okay";
		};
	};

#if 0
	/* CPU DFLL clock */
	clock@70110000 {
		status = "okay";
		nvidia,sample-rate = <11500>;
		nvidia,i2c-fs-rate = <400000>;
		vdd-cpu-supply = <&vdd_cpu>;
	};
#endif

	/* Wifi */
	sdmmc1: mmc@78000000 {
		status = "okay";

		#address-cells = <1>;
		#size-cells = <0>;

		assigned-clocks = <&tegra_car TEGRA114_CLK_SDMMC1>;
		assigned-clock-parents = <&tegra_car TEGRA114_CLK_PLL_C>;
		assigned-clock-rates = <82000000>;

		max-frequency = <82000000>;
		keep-power-in-suspend;
		bus-width = <4>;
		non-removable;

		sd-uhs-sdr104;
		mmc-ddr-1_8v;

		nvidia,default-tap = <0x2>;
		nvidia,default-trim = <0x2>;

		mmc-pwrseq = <&wl18xx_wifi_pwrseq>;
		vmmc-supply = <&vdd_3v3_com>;
		vqmmc-supply = <&vdd_1v8_vio>;

		wifi@2 {
			compatible = "ti,wl1801";
			reg = <2>;

			interrupt-parent = <&gpio>;
			interrupts = <TEGRA_GPIO(U, 5) IRQ_TYPE_LEVEL_HIGH>;

			ref-clock-frequency = <26000000>;
			tcxo-clock-frequency = <26000000>;
		};
	};

	/* MicroSD */
	sdmmc3: mmc@78000400 {
		status = "okay";
		bus-width = <4>;

		sd-uhs-sdr104;
		mmc-ddr-1_8v;

		cd-gpios = <&gpio TEGRA_GPIO(V, 2) GPIO_ACTIVE_LOW>;
		power-gpios = <&gpio TEGRA_GPIO(K, 1) GPIO_ACTIVE_HIGH>;

		nvidia,default-tap = <0x3>;
		nvidia,default-trim = <0x3>;

		vmmc-supply = <&vcore_emmc>;
		vqmmc-supply = <&vddio_usd>;
	};

	/* eMMC */
	sdmmc4: mmc@78000600 {
		status = "okay";
		bus-width = <8>;

		mmc-hs200-1_8v;
		non-removable;

		vmmc-supply = <&vcore_emmc>;
		vqmmc-supply = <&vdd_1v8_vio>;
	};

	/* Micro USB */
	usb@7d000000 {
		compatible = "nvidia,tegra114-udc";
		status = "okay";
		dr_mode = "otg";

		hnp-disable;
		srp-disable;
		adp-disable;

		usb-role-switch;
		extcon = <&bq24192>, <&palmas_extcon>; /* vbus, id */
		vbus-supply = <&usb_otg_vbus>;

		port {
			usb_in: endpoint {
				remote-endpoint = <&usb_connector_out>;
			};
		};
	};

	usb-phy@7d000000 {
		status = "okay";
		dr_mode = "otg";
		nvidia,xcvr-setup = <7>;
		nvidia,xcvr-lsfslew = <2>;
		nvidia,xcvr-lsrslew = <2>;
		vbus-supply = <&avdd_usb>;
	};

	backlight: backlight {
		compatible = "pwm-backlight";

		power-supply = <&vdd_3v7_bl>;
		pwms = <&pwm 1 1000000>;

		brightness-levels = <1 255>;
		num-interpolated-steps = <254>;
		default-brightness-level = <224>;
	};

	battery: battery-cell {
		compatible = "simple-battery";
		device-chemistry = "lithium-ion-polymer";

		charge-full-design-microamp-hours = <4100000>;
		energy-full-design-microwatt-hours = <15100000>;

		precharge-current-microamp = <256000>;
		charge-term-current-microamp = <256000>;

		operating-range-celsius = <0 45>;
	};

	clk32k_in: clock-32k {
		compatible = "fixed-clock";
		#clock-cells = <0>;
		clock-frequency = <32768>;
		clock-output-names = "ref-oscillator";
	};

	connector-hdmi {
		compatible = "hdmi-connector";
		type = "d";

		hpd-gpios = <&gpio TEGRA_GPIO(N, 7) GPIO_ACTIVE_HIGH>;
		ddc-i2c-bus = <&hdmi_ddc>;

		port {
			hdmi_connector_in: endpoint {
				remote-endpoint = <&hdmi_out>;
			};
		};
	};

	connector-usb {
		compatible = "usb-b-connector";
		type = "micro";

		port {
			usb_connector_out: endpoint {
				remote-endpoint = <&usb_in>;
			};
		};
	};

	cpus {
		cpu0: cpu@0 {
			vdd-cpu-supply = <&vdd_cpu>;
			#cooling-cells = <2>;
		};

		cpu1: cpu@1 {
			#cooling-cells = <2>;
		};

		cpu2: cpu@2 {
			#cooling-cells = <2>;
		};

		cpu3: cpu@3 {
			#cooling-cells = <2>;
		};
	};

	gpio-keys {
		compatible = "gpio-keys";

		key-power {
			label = "Power";
			gpios = <&gpio TEGRA_GPIO(Q, 0) GPIO_ACTIVE_LOW>;
			linux,code = <KEY_POWER>;
			debounce-interval = <30>;
			wakeup-source;
		};

		key-volume-up {
			label = "Volume Up";
			gpios = <&gpio TEGRA_GPIO(R, 2) GPIO_ACTIVE_LOW>;
			linux,code = <KEY_VOLUMEUP>;
			debounce-interval = <30>;
		};
	};

	wl18xx_wifi_pwrseq: pwrseq-wifi {
		compatible = "mmc-pwrseq-simple";

		reset-gpios = <&gpio TEGRA_GPIO(X, 7) GPIO_ACTIVE_LOW>;

		post-power-on-delay-ms = <100>;
		power-off-delay-us = <100>;
	};

	vdd_5v0_sys: regulator-5v0-sys {
		compatible = "regulator-fixed";
		regulator-name = "vdd_5v0_sys";
		regulator-min-microvolt = <5000000>;
		regulator-max-microvolt = <5000000>;
		regulator-always-on;
		regulator-boot-on;
	};

	vdd_3v3_sys: regulator-3v3-sys {
		compatible = "regulator-fixed";
		regulator-name = "vdd_3v3_sys";
		regulator-min-microvolt = <3300000>;
		regulator-max-microvolt = <3300000>;
		regulator-always-on;
		regulator-boot-on;
	};

	vdd_3v7_bl: regulator-bl-en {
		compatible = "regulator-fixed";
		regulator-name = "vdd_3v7_bl";
		regulator-min-microvolt = <3700000>;
		regulator-max-microvolt = <3700000>;
		regulator-boot-on;
		gpio = <&gpio TEGRA_GPIO(H, 2) GPIO_ACTIVE_HIGH>;
		enable-active-high;
		vin-supply = <&vdd_5v0_sys>;
	};

	vdd_5v0_hdmi: regulator-hdmi {
		compatible = "regulator-fixed";
		regulator-name = "vdd_5v0_hdmi";
		regulator-min-microvolt = <5000000>;
		regulator-max-microvolt = <5000000>;
		gpio = <&gpio TEGRA_GPIO(K, 6) GPIO_ACTIVE_HIGH>;
		enable-active-high;
		vin-supply = <&vdd_smps10_out2>;
	};

	vddio_1v8_cam: regulator-cam-vio {
		compatible = "regulator-fixed";
		regulator-name = "vddio_1v8_cam";
		regulator-min-microvolt = <1800000>;
		regulator-max-microvolt = <1800000>;
		regulator-boot-on;
		gpio = <&palmas_gpio 6 GPIO_ACTIVE_HIGH>;
		enable-active-high;
		vin-supply = <&vdd_1v8_vio>;
	};

	dvdd_lcd: regulator-lcd {
		compatible = "regulator-fixed";
		regulator-name = "dvdd_1v8_lcd";
		regulator-min-microvolt = <1800000>;
		regulator-max-microvolt = <1800000>;
		regulator-boot-on;
		gpio = <&palmas_gpio 4 GPIO_ACTIVE_HIGH>;
		enable-active-high;
		vin-supply = <&vdd_1v8_vio>;
	};

	dvdd_touch: regulator-ts {
		compatible = "regulator-fixed";
		regulator-name = "dvdd_1v8_ts";
		regulator-min-microvolt = <1800000>;
		regulator-max-microvolt = <1800000>;
		enable-active-high;
		vin-supply = <&vdd_1v8_vio>;
	};

	vlogic_gyro: regulator-gyro {
		compatible = "regulator-fixed";
		regulator-name = "vlogic_gyro";
		regulator-min-microvolt = <1800000>;
		regulator-max-microvolt = <1800000>;
		vin-supply = <&vdd_1v8_vio>;
	};

	avdd_hdmi_pll: regulator-hdmi-pll {
		compatible = "regulator-fixed";
		regulator-name = "avdd_hdmi_pll";
		regulator-min-microvolt = <1050000>;
		regulator-max-microvolt = <1050000>;
		vin-supply = <&avdd_csi_dsi_pll>;
	};

	vdd_3v3_com: regulator-com {
		compatible = "regulator-fixed";
		regulator-name = "vdd_3v3_com";
		regulator-min-microvolt = <3300000>;
		regulator-max-microvolt = <3300000>;
		regulator-boot-on;
		gpio = <&gpio TEGRA_GPIO(CC, 5) GPIO_ACTIVE_HIGH>;
		enable-active-high;
		vin-supply = <&vdd_3v3_sys>;
	};

	sound {
		nvidia,audio-routing =
			"Headphone Jack", "HPOR",
			"Headphone Jack", "HPOL",
			"Int Spk", "SPORP",
			"Int Spk", "SPORN",
			"Int Spk", "SPOLP",
			"Int Spk", "SPOLN",
			"IN1P", "Mic Jack",
			"IN1N", "Mic Jack",
			"DMIC1", "Int Mic",
			"DMIC2", "Int Mic";

		nvidia,i2s-controller = <&tegra_i2s1>;

		nvidia,hp-det-gpios = <&gpio TEGRA_GPIO(R, 7) GPIO_ACTIVE_LOW>; // check
		nvidia,int-mic-en-gpios = <&gpio TEGRA_GPIO(K, 3) GPIO_ACTIVE_HIGH>;

		clocks = <&tegra_car TEGRA114_CLK_PLL_A>,
			 <&tegra_car TEGRA114_CLK_PLL_A_OUT0>,
			 <&tegra_pmc TEGRA_PMC_CLK_OUT_1>;
		clock-names = "pll_a", "pll_a_out0", "mclk";

		assigned-clocks = <&tegra_car TEGRA114_CLK_EXTERN1>,
				  <&tegra_pmc TEGRA_PMC_CLK_OUT_1>;

		assigned-clock-parents = <&tegra_car TEGRA114_CLK_PLL_A_OUT0>,
					 <&tegra_car TEGRA114_CLK_EXTERN1>;
	};
};
